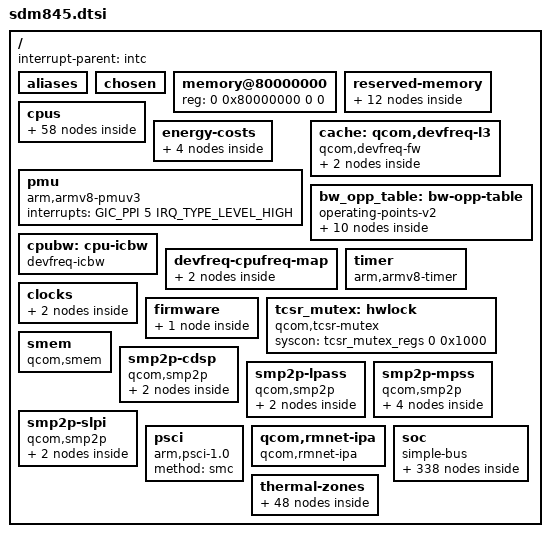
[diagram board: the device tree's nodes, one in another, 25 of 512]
// SPDX-License-Identifier: GPL-2.0
/*
 * SDM845 SoC device tree source
 *
 * Copyright (c) 2018, The Linux Foundation. All rights reserved.
 */

#include <dt-bindings/clock/qcom,aop-qmp.h>
#include <dt-bindings/clock/qcom,dispcc-sdm845.h>
#include <dt-bindings/clock/qcom,gcc-sdm845.h>
#include <dt-bindings/clock/qcom,gpucc-sdm845.h>
#include <dt-bindings/clock/qcom,rpmh.h>
#include <dt-bindings/clock/qcom,videocc-sdm845.h>
#include <dt-bindings/interrupt-controller/arm-gic.h>
#include <dt-bindings/phy/phy-qcom-qusb2.h>
#include <dt-bindings/power/qcom-rpmpd.h>
#include <dt-bindings/reset/qcom,sdm845-aoss.h>
#include <dt-bindings/reset/qcom,sdm845-pdc.h>
#include <dt-bindings/soc/qcom,dcc_v2.h>
#include <dt-bindings/soc/qcom,rpmh-rsc.h>
#include <dt-bindings/soc/qcom,ipa.h>
#include <dt-bindings/thermal/thermal.h>

/ {
	interrupt-parent = <&intc>;

	#address-cells = <2>;
	#size-cells = <2>;

	aliases {
		i2c0 = &i2c0;
		i2c1 = &i2c1;
		i2c2 = &i2c2;
		i2c3 = &i2c3;
		i2c4 = &i2c4;
		i2c5 = &i2c5;
		i2c6 = &i2c6;
		i2c7 = &i2c7;
		i2c8 = &i2c8;
		i2c9 = &i2c9;
		i2c10 = &i2c10;
		i2c11 = &i2c11;
		i2c12 = &i2c12;
		i2c13 = &i2c13;
		i2c14 = &i2c14;
		i2c15 = &i2c15;
		spi0 = &spi0;
		spi1 = &spi1;
		spi2 = &spi2;
		spi3 = &spi3;
		spi4 = &spi4;
		spi5 = &spi5;
		spi6 = &spi6;
		spi7 = &spi7;
		spi8 = &spi8;
		spi9 = &spi9;
		spi10 = &spi10;
		spi11 = &spi11;
		spi12 = &spi12;
		spi13 = &spi13;
		spi14 = &spi14;
		spi15 = &spi15;
	};

	chosen { };

	memory@80000000 {
		device_type = "memory";
		/* We expect the bootloader to fill in the size */
		reg = <0 0x80000000 0 0>;
	};

	reserved-memory {
		#address-cells = <2>;
		#size-cells = <2>;
		ranges;

		memory@85fc0000 {
			reg = <0 0x85fc0000 0 0x20000>;
			no-map;
		};

		memory@85fe0000 {
			compatible = "qcom,cmd-db";
			reg = <0x0 0x85fe0000 0x0 0x20000>;
			no-map;
		};

		smem_mem: memory@86000000 {
			reg = <0x0 0x86000000 0x0 0x200000>;
			no-map;
		};

		memory@86200000 {
			reg = <0 0x86200000 0 0x2d00000>;
			no-map;
		};

		rmtfs_mem: rmtfs@88f00000 {
			compatible = "qcom,rmtfs-mem";
			reg = <0x0 0x88f00000 0x0 0x200000>;
			no-map;

			qcom,client-id = <1>;
		};

		pil_adsp_mem: reserved-memory@8b100000 {
			no-map;
			reg = <0 0x8b100000 0 0x1a00000>;
		};

		mpss_mem: reserved-memory@8e000000 {
			no-map;
			reg = <0 0x8e000000 0 0x7800000>;
		};

		venus_region: venus@95800000 {
			reg = <0x0 0x95800000 0x0 0x500000>;
			no-map;
		};

		mba_mem: reserved-memory@96500000 {
			no-map;
			reg = <0 0x96500000 0 0x200000>;
		};

		wlan_msa_mem: wlan_msa_region@96700000 {
			no-map;
			reg = <0 0x96700000 0 0x100000>;
		};

		dump_mem: mem_dump_region {
			compatible = "shared-dma-pool";
			reusable;
			size = <0 0x2400000>;
		};

		/* global autoconfigured region for contiguous allocations */
		linux,cma {
			compatible = "shared-dma-pool";
			alloc-ranges = <0 0x00000000 0 0xffffffff>;
			reusable;
			alignment = <0 0x400000>;
			size = <0 0x2800000>;
			linux,cma-default;
		};
	};

	cpus {
		#address-cells = <2>;
		#size-cells = <0>;

		CPU0: cpu@0 {
			device_type = "cpu";
			compatible = "qcom,kryo385";
			reg = <0x0 0x0>;
			enable-method = "psci";
			next-level-cache = <&L2_0>;
			cpu-idle-states = <&C0_CPU_PD &C0_CPU_RPD &CLUSTER_PD>;
			qcom,freq-domain = <&cpufreq_hw 0>;
			capacity-dmips-mhz = <607>;
			sched-energy-costs = <&SDM845_CPU_COST_0 &SDM845_CLUSTER_COST_0>;
			freq-energy-model;
			#cooling-cells = <2>; /* min followed by max */
			power-domains = <&cpu_pd>;

			L2_0: l2-cache {
				compatible = "cache";
				next-level-cache = <&L3_0>;
				L3_0: l3-cache {
				      compatible = "cache";
				};
			};

			L1_I_0: l1-icache {
				compatible = "cache";
				qcom,dump-size = <0x9000>;
			};

			L1_D_0: l1-dcache {
				compatible = "cache";
				qcom,dump-size = <0x9000>;
			};

			L1_TLB_0: l1-tlb {
				qcom,dump-size = <0x6000>;
			};
		};

		CPU1: cpu@100 {
			device_type = "cpu";
			compatible = "qcom,kryo385";
			reg = <0x0 0x100>;
			enable-method = "psci";
			next-level-cache = <&L2_100>;
			cpu-idle-states = <&C0_CPU_PD &C0_CPU_RPD &CLUSTER_PD>;
			qcom,freq-domain = <&cpufreq_hw 0>;
			capacity-dmips-mhz = <607>;
			sched-energy-costs = <&SDM845_CPU_COST_0 &SDM845_CLUSTER_COST_0>;
			freq-energy-model;
			power-domains = <&cpu_pd>;

			L2_100: l2-cache {
				compatible = "cache";
				next-level-cache = <&L3_0>;
			};

			L1_I_100: l1-icache {
				compatible = "cache";
				qcom,dump-size = <0x9000>;
			};

			L1_D_100: l1-dcache {
				compatible = "cache";
				qcom,dump-size = <0x9000>;
			};

			L1_TLB_100: l1-tlb {
				qcom,dump-size = <0x6000>;
			};
		};

		CPU2: cpu@200 {
			device_type = "cpu";
			compatible = "qcom,kryo385";
			reg = <0x0 0x200>;
			enable-method = "psci";
			next-level-cache = <&L2_200>;
			cpu-idle-states = <&C0_CPU_PD &C0_CPU_RPD &CLUSTER_PD>;
			qcom,freq-domain = <&cpufreq_hw 0>;
			capacity-dmips-mhz = <607>;
			sched-energy-costs = <&SDM845_CPU_COST_0 &SDM845_CLUSTER_COST_0>;
			freq-energy-model;
			power-domains = <&cpu_pd>;

			L2_200: l2-cache {
				compatible = "cache";
				next-level-cache = <&L3_0>;
			};

			L1_I_200: l1-icache {
				compatible = "cache";
				qcom,dump-size = <0x9000>;
			};

			L1_D_200: l1-dcache {
				compatible = "cache";
				qcom,dump-size = <0x9000>;
			};

			L1_TLB_200: l1-tlb {
				qcom,dump-size = <0x6000>;
			};
		};

		CPU3: cpu@300 {
			device_type = "cpu";
			compatible = "qcom,kryo385";
			reg = <0x0 0x300>;
			enable-method = "psci";
			next-level-cache = <&L2_300>;
			cpu-idle-states = <&C0_CPU_PD &C0_CPU_RPD &CLUSTER_PD>;
			qcom,freq-domain = <&cpufreq_hw 0>;
			capacity-dmips-mhz = <607>;
			sched-energy-costs = <&SDM845_CPU_COST_0 &SDM845_CLUSTER_COST_0>;
			freq-energy-model;
			power-domains = <&cpu_pd>;

			L2_300: l2-cache {
				compatible = "cache";
				next-level-cache = <&L3_0>;
			};

			L1_I_300: l1-icache {
				compatible = "cache";
				qcom,dump-size = <0x9000>;
			};

			L1_D_300: l1-dcache {
				compatible = "cache";
				qcom,dump-size = <0x9000>;
			};

			L1_TLB_300: l1-tlb {
				qcom,dump-size = <0x6000>;
			};
		};

		CPU4: cpu@400 {
			device_type = "cpu";
			compatible = "qcom,kryo385";
			reg = <0x0 0x400>;
			enable-method = "psci";
			next-level-cache = <&L2_400>;
			cpu-idle-states = <&C4_CPU_PD &C4_CPU_RPD &CLUSTER_PD>;
			capacity-dmips-mhz = <1024>;
			qcom,freq-domain = <&cpufreq_hw 1>;
			sched-energy-costs = <&SDM845_CPU_COST_1 &SDM845_CLUSTER_COST_1>;
			freq-energy-model;
			#cooling-cells = <2>; /* min followed by max */
			power-domains = <&cpu_pd>;

			L2_400: l2-cache {
				compatible = "cache";
				next-level-cache = <&L3_0>;
			};

			L1_I_400: l1-icache {
				compatible = "cache";
				qcom,dump-size = <0x12000>;
			};

			L1_D_400: l1-dcache {
				compatible = "cache";
				qcom,dump-size = <0x12000>;
			};

			L1_TLB_400: l1-tlb {
				qcom,dump-size = <0x6800>;
			};
		};

		CPU5: cpu@500 {
			device_type = "cpu";
			compatible = "qcom,kryo385";
			reg = <0x0 0x500>;
			enable-method = "psci";
			next-level-cache = <&L2_500>;
			cpu-idle-states = <&C4_CPU_PD &C4_CPU_RPD &CLUSTER_PD>;
			qcom,freq-domain = <&cpufreq_hw 1>;
			capacity-dmips-mhz = <1024>;
			sched-energy-costs = <&SDM845_CPU_COST_1 &SDM845_CLUSTER_COST_1>;
			freq-energy-model;
			power-domains = <&cpu_pd>;

			L2_500: l2-cache {
				compatible = "cache";
				next-level-cache = <&L3_0>;
			};

			L1_I_500: l1-icache {
				compatible = "cache";
				qcom,dump-size = <0x12000>;
			};

			L1_D_500: l1-dcache {
				compatible = "cache";
				qcom,dump-size = <0x12000>;
			};

			L1_TLB_500: l1-tlb {
				qcom,dump-size = <0x6800>;
			};
		};

		CPU6: cpu@600 {
			device_type = "cpu";
			compatible = "qcom,kryo385";
			reg = <0x0 0x600>;
			enable-method = "psci";
			next-level-cache = <&L2_600>;
			cpu-idle-states = <&C4_CPU_PD &C4_CPU_RPD &CLUSTER_PD>;
			qcom,freq-domain = <&cpufreq_hw 1>;
			capacity-dmips-mhz = <1024>;
			sched-energy-costs = <&SDM845_CPU_COST_1 &SDM845_CLUSTER_COST_1>;
			freq-energy-model;
			power-domains = <&cpu_pd>;

			L2_600: l2-cache {
				compatible = "cache";
				next-level-cache = <&L3_0>;
			};

			L1_I_600: l1-icache {
				compatible = "cache";
				qcom,dump-size = <0x12000>;
			};

			L1_D_600: l1-dcache {
				compatible = "cache";
				qcom,dump-size = <0x12000>;
			};

			L1_TLB_600: l1-tlb {
				qcom,dump-size = <0x6800>;
			};
		};

		CPU7: cpu@700 {
			device_type = "cpu";
			compatible = "qcom,kryo385";
			reg = <0x0 0x700>;
			enable-method = "psci";
			next-level-cache = <&L2_700>;
			cpu-idle-states = <&C4_CPU_PD &C4_CPU_RPD &CLUSTER_PD>;
			qcom,freq-domain = <&cpufreq_hw 1>;
			capacity-dmips-mhz = <1024>;
			sched-energy-costs = <&SDM845_CPU_COST_1 &SDM845_CLUSTER_COST_1>;
			freq-energy-model;
			power-domains = <&cpu_pd>;

			L2_700: l2-cache {
				compatible = "cache";
				next-level-cache = <&L3_0>;
			};

			L1_I_700: l1-icache {
				compatible = "cache";
				qcom,dump-size = <0x12000>;
			};

			L1_D_700: l1-dcache {
				compatible = "cache";
				qcom,dump-size = <0x12000>;
			};

			L1_TLB_700: l1-tlb {
				qcom,dump-size = <0x6800>;
			};
		};

		cpu-map {
			cluster0 {
				core0 {
					cpu = <&CPU0>;
				};

				core1 {
					cpu = <&CPU1>;
				};

				core2 {
					cpu = <&CPU2>;
				};

				core3 {
					cpu = <&CPU3>;
				};
			};

			cluster1 {
				core0 {
					cpu = <&CPU4>;
				};

				core1 {
					cpu = <&CPU5>;
				};

				core2 {
					cpu = <&CPU6>;
				};

				core3 {
					cpu = <&CPU7>;
				};
			};
		};

		idle-states {
			entry-method = "psci";

			C0_CPU_PD: c0-power-down {
				compatible = "arm,idle-state";
				arm,psci-suspend-param = <0x40000003>;
				entry-latency-us = <350>;
				exit-latency-us = <461>;
				min-residency-us = <1890>;
				local-timer-stop;
				idle-state-name = "power-down";
			};

			C0_CPU_RPD: c0-rail-power-down {
				compatible = "arm,idle-state";
				arm,psci-suspend-param = <0x40000004>;
				entry-latency-us = <360>;
				exit-latency-us = <531>;
				min-residency-us = <3934>;
				local-timer-stop;
				idle-state-name = "rail-power-down";
			};

			C4_CPU_PD: c4-power-down {
				compatible = "arm,idle-state";
				arm,psci-suspend-param = <0x40000003>;
				entry-latency-us = <264>;
				exit-latency-us = <621>;
				min-residency-us = <952>;
				local-timer-stop;
				idle-state-name = "power-down";
			};

			C4_CPU_RPD: c4-rail-power-down {
				compatible = "arm,idle-state";
				arm,psci-suspend-param = <0x40000004>;
				entry-latency-us = <702>;
				exit-latency-us = <1061>;
				min-residency-us = <4488>;
				local-timer-stop;
				idle-state-name = "rail-power-down";
			};

			CLUSTER_PD: cluster-power-down {
				compatible = "arm,idle-state";
				arm,psci-suspend-param = <0x400000F4>;
				entry-latency-us = <3263>;
				exit-latency-us = <6562>;
				min-residency-us = <9987>;
				local-timer-stop;
				idle-state-name = "cluster-power-down";
			};
		};
	};

	energy-costs {
		SDM845_CPU_COST_0: sdm845-core-cost0 {
			busy-cost-data = <
				 300000 12
				 403200 17
				 480000 21
				 576000 27
				 652800 31
				 748800 37
				 825600 42
				 902400 47
				 979200 52
				1056000 57
				1132800 62
				1228800 70
				1324800 78
				1420800 89
				1516800 103
				1612800 122
				1689600 141
				1766400 160
			>;
			idle-cost-data = <
				10 8 6 4
			>;
		};

		SDM845_CPU_COST_1: sdm845-core-cost1 {
			busy-cost-data = <
				 300000 189
				 403200 523
				 480000 763
				 576000 1052
				 652800 1273
				 748800 1536
				 825600 1736
				 902400 1926
				 979200 2108
				1056000 2284
				1132800 2456
				1209600 2628
				1286400 2804
				1363200 2992
				1459200 3255
				1536000 3499
				1612800 3786
				1689600 4128
				1766400 4535
				1843200 5019
				1920000 5583
				1996800 6226
				2092800 7120
				2169600 7876
				2246400 8628
				2323200 9344
				2400000 10030
				2476800 10806
				2553600 12045
				2649600 15686
				2707200 19978
				2745600 25586
				2764800 30000
				2784000 35000
				2803200 40000
				2841600 50000
				2956800 60000
			>;
			idle-cost-data = <
				100 80 60 40
			>;
		};

		SDM845_CLUSTER_COST_0: sdm845-cluster-cost0 {
			busy-cost-data = <
				 300000 3
				 403200 4
				 480000 4
				 576000 4
				 652800 5
				 748800 5
				 825600 6
				 902400 7
				 979200 7
				1056000 8
				1132800 9
				1228800 9
				1324800 10
				1420800 11
				1516800 12
				1612800 13
				1689600 15
				1766400 17
			>;
			idle-cost-data = <
				4 3 2 1
			>;
		};

		SDM845_CLUSTER_COST_1: sdm845-cluster-cost1 {
			busy-cost-data = <
				 300000  24
				 403200  24
				 480000  25
				 576000  25
				 652800  26
				 748800  27
				 825600  28
				 902400  29
				 979200  30
				1056000  32
				1132800  34
				1209600  37
				1286400  40
				1363200  45
				1459200  50
				1536000  57
				1612800  64
				1689600  74
				1766400  84
				1843200  96
				1920000 106
				1996800 113
				2092800 120
				2169600 125
				2246400 127
				2323200 130
				2400000 135
				2476800 140
				2553600 145
				2649600 150
				2707200 153
				2745600 155
				2764800 160
				2784000 165
				2803200 170
				2841600 180
				2956800 190
			>;
			idle-cost-data = <
				4 3 2 1
			>;
		};
	};

	pmu {
		compatible = "arm,armv8-pmuv3";
		interrupts = <GIC_PPI 5 IRQ_TYPE_LEVEL_HIGH>;
	};

	cache: qcom,devfreq-l3 {
	       compatible = "qcom,devfreq-fw";
	       reg-names = "en-base", "ftbl-base", "perf-base";
	       reg = <0x0 0x17d41000 0x0 0x4>,
		     <0x0 0x17d41110 0x0 0x600>,
		     <0x0 0x17d41920 0x0 0x4>;

	       qcom,cpu0-l3 {
		       compatible = "qcom,devfreq-fw-voter";
	       };

	       qcom,cpu4-l3 {
		       compatible = "qcom,devfreq-fw-voter";
	       };
	};

	bw_opp_table: bw-opp-table {
		compatible = "operating-points-v2";
		opp-200  {
			opp-hz = /bits/ 64 < 781250 >; /* 200 MHz */
		};
		opp-300 {
			opp-hz = /bits/ 64 < 1171875 >; /* 300 MHz */
		};
		opp-451 {
			opp-hz = /bits/ 64 < 1761718 >; /* 451 MHz */
		};
		opp-547 {
			opp-hz = /bits/ 64 < 2136718 >; /* 547 MHz */
		};
		opp-681 {
			opp-hz = /bits/ 64 < 2660156 >; /* 681 MHz */
		};
		opp-768 {
			opp-hz = /bits/ 64 < 3000000 >; /* 768 MHz */
		};
		opp-1017 {
			opp-hz = /bits/ 64 < 3972656 >; /* 1017 MHz */
		};
		opp-1296 {
			opp-hz = /bits/ 64 < 5062500 >; /* 1296 MHz */
		};
		opp-1555 {
			opp-hz = /bits/ 64 < 6074218 >; /* 1555 MHz */
		};
		opp-1804 {
			opp-hz = /bits/ 64 < 7046875 >; /* 1804 MHz */
		};
	};

	cpubw: cpu-icbw {
		compatible = "devfreq-icbw";
		interconnects = <&qnoc 0 &qnoc 512>;
		operating-points-v2 = <&bw_opp_table>;
	};

	devfreq-cpufreq-map {
		cache-cpufreq {
		       target-dev = <&cache>;
		       cpu-to-dev-map =
				<  300000  300000 >,
				<  480000  403200 >,
				<  652800  480000 >,
				<  748800  576000 >,
				<  902400  652800 >,
				<  979200  748800 >,
				< 1132800  844800 >,
				< 1228800  940800 >,
				< 1324800 1036800 >,
				< 1420800 1132800 >,
				< 1516800 1209600 >,
				< 1689600 1305600 >,
				< 1766400 1401600 >,
				< 2745600 1593600 >;
		};

		cpubw-cpufreq {
		       target-dev = <&cpubw>;
		       cpu-to-dev-map =
				<  300000 1171875 >,
				<  422400 2660156 >,
				<  652800 3000000 >,
				<  883200 6074218 >,
				< 1190400 7046875 >;
		};
	};

	timer {
		compatible = "arm,armv8-timer";
		interrupts = <GIC_PPI 1 IRQ_TYPE_LEVEL_LOW>,
			     <GIC_PPI 2 IRQ_TYPE_LEVEL_LOW>,
			     <GIC_PPI 3 IRQ_TYPE_LEVEL_LOW>,
			     <GIC_PPI 0 IRQ_TYPE_LEVEL_LOW>;
	};

	clocks {
		xo_board: xo-board {
			compatible = "fixed-clock";
			#clock-cells = <0>;
			clock-frequency = <38400000>;
			clock-output-names = "xo_board";
		};

		sleep_clk: sleep-clk {
			compatible = "fixed-clock";
			#clock-cells = <0>;
			clock-frequency = <32764>;
		};
	};

	firmware {
		/* TODO: does this really belong in SoC dtsi file? */
		scm {
			compatible = "qcom,scm-msm8996";
		};
	};

	tcsr_mutex: hwlock {
		compatible = "qcom,tcsr-mutex";
		syscon = <&tcsr_mutex_regs 0 0x1000>;
		#hwlock-cells = <1>;
	};

	smem {
		compatible = "qcom,smem";
		memory-region = <&smem_mem>;
		hwlocks = <&tcsr_mutex 3>;
	};

	smp2p-cdsp {
		compatible = "qcom,smp2p";
		qcom,smem = <94>, <432>;

		interrupts = <GIC_SPI 576 IRQ_TYPE_EDGE_RISING>;

		mboxes = <&apss_shared 6>;

		qcom,local-pid = <0>;
		qcom,remote-pid = <5>;

		cdsp_smp2p_out: master-kernel {
			qcom,entry-name = "master-kernel";
			#qcom,smem-state-cells = <1>;
		};

		cdsp_smp2p_in: slave-kernel {
			qcom,entry-name = "slave-kernel";

			interrupt-controller;
			#interrupt-cells = <2>;
		};
	};

	smp2p-lpass {
		compatible = "qcom,smp2p";
		qcom,smem = <443>, <429>;

		interrupts = <GIC_SPI 158 IRQ_TYPE_EDGE_RISING>;

		mboxes = <&apss_shared 10>;

		qcom,local-pid = <0>;
		qcom,remote-pid = <2>;

		adsp_smp2p_out: master-kernel {
			qcom,entry-name = "master-kernel";
			#qcom,smem-state-cells = <1>;
		};

		adsp_smp2p_in: slave-kernel {
			qcom,entry-name = "slave-kernel";

			interrupt-controller;
			#interrupt-cells = <2>;
		};
	};

	smp2p-mpss {
		compatible = "qcom,smp2p";
		qcom,smem = <435>, <428>;
		interrupts = <GIC_SPI 451 IRQ_TYPE_EDGE_RISING>;
		mboxes = <&apss_shared 14>;
		qcom,local-pid = <0>;
		qcom,remote-pid = <1>;

		modem_smp2p_out: master-kernel {
			qcom,entry-name = "master-kernel";
			#qcom,smem-state-cells = <1>;
		};

		modem_smp2p_in: slave-kernel {
			qcom,entry-name = "slave-kernel";
			interrupt-controller;
			#interrupt-cells = <2>;
		};

		ipa_smp2p_out: ipa-ap-to-modem {
			qcom,entry-name = "ipa";
			#qcom,smem-state-cells = <1>;
		};

		ipa_smp2p_in: ipa-modem-to-ap {
			qcom,entry-name = "ipa";
			interrupt-controller;
			#interrupt-cells = <2>;
		};
	};

	smp2p-slpi {
		compatible = "qcom,smp2p";
		qcom,smem = <481>, <430>;
		interrupts = <GIC_SPI 172 IRQ_TYPE_EDGE_RISING>;
		mboxes = <&apss_shared 26>;
		qcom,local-pid = <0>;
		qcom,remote-pid = <3>;

		slpi_smp2p_out: master-kernel {
			qcom,entry-name = "master-kernel";
			#qcom,smem-state-cells = <1>;
		};

		slpi_smp2p_in: slave-kernel {
			qcom,entry-name = "slave-kernel";
			interrupt-controller;
			#interrupt-cells = <2>;
		};
	};

	psci {
		compatible = "arm,psci-1.0";
		method = "smc";
	};

	qcom,rmnet-ipa {
		compatible = "qcom,rmnet-ipa";
	};

	soc: soc {
		#address-cells = <1>;
		#size-cells = <1>;
		ranges = <0 0 0 0xffffffff>;
		compatible = "simple-bus";

		maxvoter {
			compatible = "qcom,maxvoter";
			power-domains = <&rpmhpd SDM845_MX>,
					<&rpmhpd SDM845_CX>;
			power-domain-names = "mx", "cx";
		};

		cpuss_dump {
			compatible = "qcom,cpuss-dump";
			qcom,l1_i_cache0 {
				qcom,dump-node = <&L1_I_0>;
				qcom,dump-id = <0x60>;
			};
			qcom,l1_i_cache1 {
				qcom,dump-node = <&L1_I_100>;
				qcom,dump-id = <0x61>;
			};
			qcom,l1_i_cache2 {
				qcom,dump-node = <&L1_I_200>;
				qcom,dump-id = <0x62>;
			};
			qcom,l1_i_cache3 {
				qcom,dump-node = <&L1_I_300>;
				qcom,dump-id = <0x63>;
			};
			qcom,l1_i_cache100 {
				qcom,dump-node = <&L1_I_400>;
				qcom,dump-id = <0x64>;
			};
			qcom,l1_i_cache101 {
				qcom,dump-node = <&L1_I_500>;
				qcom,dump-id = <0x65>;
			};
			qcom,l1_i_cache102 {
				qcom,dump-node = <&L1_I_600>;
				qcom,dump-id = <0x66>;
			};
			qcom,l1_i_cache103 {
				qcom,dump-node = <&L1_I_700>;
				qcom,dump-id = <0x67>;
			};
			qcom,l1_d_cache0 {
				qcom,dump-node = <&L1_D_0>;
				qcom,dump-id = <0x80>;
			};
			qcom,l1_d_cache1 {
				qcom,dump-node = <&L1_D_100>;
				qcom,dump-id = <0x81>;
			};
			qcom,l1_d_cache2 {
				qcom,dump-node = <&L1_D_200>;
				qcom,dump-id = <0x82>;
			};
			qcom,l1_d_cache3 {
				qcom,dump-node = <&L1_D_300>;
				qcom,dump-id = <0x83>;
			};
			qcom,l1_d_cache100 {
				qcom,dump-node = <&L1_D_400>;
				qcom,dump-id = <0x84>;
			};
			qcom,l1_d_cache101 {
				qcom,dump-node = <&L1_D_500>;
				qcom,dump-id = <0x85>;
			};
			qcom,l1_d_cache102 {
				qcom,dump-node = <&L1_D_600>;
				qcom,dump-id = <0x86>;
			};
			qcom,l1_d_cache103 {
				qcom,dump-node = <&L1_D_700>;
				qcom,dump-id = <0x87>;
			};
			qcom,l1_tlb_dump0 {
				qcom,dump-node = <&L1_TLB_0>;
				qcom,dump-id = <0x120>;
			};
			qcom,l1_tlb_dump100 {
				qcom,dump-node = <&L1_TLB_100>;
				qcom,dump-id = <0x121>;
			};
			qcom,l1_tlb_dump200 {
				qcom,dump-node = <&L1_TLB_200>;
				qcom,dump-id = <0x122>;
			};
			qcom,l1_tlb_dump300 {
				qcom,dump-node = <&L1_TLB_300>;
				qcom,dump-id = <0x123>;
			};
			qcom,l1_tlb_dump400 {
				qcom,dump-node = <&L1_TLB_400>;
				qcom,dump-id = <0x124>;
			};
			qcom,l1_tlb_dump500 {
				qcom,dump-node = <&L1_TLB_500>;
				qcom,dump-id = <0x125>;
			};
			qcom,l1_tlb_dump600 {
				qcom,dump-node = <&L1_TLB_600>;
				qcom,dump-id = <0x126>;
			};
			qcom,l1_tlb_dump700 {
				qcom,dump-node = <&L1_TLB_700>;
				qcom,dump-id = <0x127>;
			};
		};

		gcc: clock-controller@100000 {
			compatible = "qcom,gcc-sdm845";
			reg = <0x100000 0x1f0000>;
			#clock-cells = <1>;
			#reset-cells = <1>;
			#power-domain-cells = <1>;
		};

		lpasscc: clock-controller {
			compatible = "qcom,sdm845-lpasscc";
			reg = <0x17014000 0x1f004>, <0x17300000 0x200>;
			reg-names = "lpass_cc", "lpass_qdsp6ss";
			#clock-cells = <1>;
		};

		clock_aop: qcom,aopclk {
			compatible = "qcom,aop-qmp-clk";
			#clock-cells = <1>;
			mboxes = <&qmp_aop 0>;
			mbox-names = "qdss_clk";
		};

		qfprom@784000 {
			compatible = "qcom,qfprom";
			reg = <0x784000 0x8ff>;
			#address-cells = <1>;
			#size-cells = <1>;

			qusb2p_hstx_trim: hstx-trim-primary@1eb {
				reg = <0x1eb 0x1>;
				bits = <1 4>;
			};

			qusb2s_hstx_trim: hstx-trim-secondary@1eb {
				reg = <0x1eb 0x2>;
				bits = <6 4>;
			};
		};

		qupv3_id_0: geniqup@8c0000 {
			compatible = "qcom,geni-se-qup";
			reg = <0x8c0000 0x6000>;
			clock-names = "m-ahb", "s-ahb";
			clocks = <&gcc GCC_QUPV3_WRAP_0_M_AHB_CLK>,
				 <&gcc GCC_QUPV3_WRAP_0_S_AHB_CLK>;
			#address-cells = <1>;
			#size-cells = <1>;
			ranges;
			status = "disabled";

			i2c0: i2c@880000 {
				compatible = "qcom,geni-i2c";
				reg = <0x880000 0x4000>;
				clock-names = "se";
				clocks = <&gcc GCC_QUPV3_WRAP0_S0_CLK>;
				pinctrl-names = "default";
				pinctrl-0 = <&qup_i2c0_default>;
				interrupts = <GIC_SPI 601 IRQ_TYPE_LEVEL_HIGH>;
				#address-cells = <1>;
				#size-cells = <0>;

				interconnects = <&qnoc 11 &qnoc 512>,
						<&qnoc 0 &qnoc 543>;
				interconnect-names = "memory", "config";

				status = "disabled";
			};

			spi0: spi@880000 {
				compatible = "qcom,geni-spi";
				reg = <0x880000 0x4000>;
				clock-names = "se";
				clocks = <&gcc GCC_QUPV3_WRAP0_S0_CLK>;
				pinctrl-names = "default";
				pinctrl-0 = <&qup_spi0_default>;
				interrupts = <GIC_SPI 601 IRQ_TYPE_LEVEL_HIGH>;
				#address-cells = <1>;
				#size-cells = <0>;

				interconnects = <&qnoc 11 &qnoc 512>,
						<&qnoc 0 &qnoc 543>;
				interconnect-names = "memory", "config";

				status = "disabled";
			};

			uart0: serial@880000 {
				compatible = "qcom,geni-uart";
				reg = <0x880000 0x4000>;
				clock-names = "se";
				clocks = <&gcc GCC_QUPV3_WRAP0_S0_CLK>;
				pinctrl-names = "default";
				pinctrl-0 = <&qup_uart0_default>;
				interrupts = <GIC_SPI 601 IRQ_TYPE_LEVEL_HIGH>;
				status = "disabled";
			};

			i2c1: i2c@884000 {
				compatible = "qcom,geni-i2c";
				reg = <0x884000 0x4000>;
				clock-names = "se";
				clocks = <&gcc GCC_QUPV3_WRAP0_S1_CLK>;
				pinctrl-names = "default";
				pinctrl-0 = <&qup_i2c1_default>;
				interrupts = <GIC_SPI 602 IRQ_TYPE_LEVEL_HIGH>;
				#address-cells = <1>;
				#size-cells = <0>;

				interconnects = <&qnoc 11 &qnoc 512>,
						<&qnoc 0 &qnoc 543>;
				interconnect-names = "memory", "config";

				status = "disabled";
			};

			spi1: spi@884000 {
				compatible = "qcom,geni-spi";
				reg = <0x884000 0x4000>;
				clock-names = "se";
				clocks = <&gcc GCC_QUPV3_WRAP0_S1_CLK>;
				pinctrl-names = "default";
				pinctrl-0 = <&qup_spi1_default>;
				interrupts = <GIC_SPI 602 IRQ_TYPE_LEVEL_HIGH>;
				#address-cells = <1>;
				#size-cells = <0>;

				interconnects = <&qnoc 11 &qnoc 512>,
						<&qnoc 0 &qnoc 543>;
				interconnect-names = "memory", "config";

				status = "disabled";
			};

			uart1: serial@884000 {
				compatible = "qcom,geni-uart";
				reg = <0x884000 0x4000>;
				clock-names = "se";
				clocks = <&gcc GCC_QUPV3_WRAP0_S1_CLK>;
				pinctrl-names = "default";
				pinctrl-0 = <&qup_uart1_default>;
				interrupts = <GIC_SPI 602 IRQ_TYPE_LEVEL_HIGH>;
				status = "disabled";
			};

			i2c2: i2c@888000 {
				compatible = "qcom,geni-i2c";
				reg = <0x888000 0x4000>;
				clock-names = "se";
				clocks = <&gcc GCC_QUPV3_WRAP0_S2_CLK>;
				pinctrl-names = "default";
				pinctrl-0 = <&qup_i2c2_default>;
				interrupts = <GIC_SPI 603 IRQ_TYPE_LEVEL_HIGH>;
				#address-cells = <1>;
				#size-cells = <0>;

				interconnects = <&qnoc 11 &qnoc 512>,
						<&qnoc 0 &qnoc 543>;
				interconnect-names = "memory", "config";

				status = "disabled";
			};

			spi2: spi@888000 {
				compatible = "qcom,geni-spi";
				reg = <0x888000 0x4000>;
				clock-names = "se";
				clocks = <&gcc GCC_QUPV3_WRAP0_S2_CLK>;
				pinctrl-names = "default";
				pinctrl-0 = <&qup_spi2_default>;
				interrupts = <GIC_SPI 603 IRQ_TYPE_LEVEL_HIGH>;
				#address-cells = <1>;
				#size-cells = <0>;

				interconnects = <&qnoc 11 &qnoc 512>,
						<&qnoc 0 &qnoc 543>;
				interconnect-names = "memory", "config";

				status = "disabled";
			};

			uart2: serial@888000 {
				compatible = "qcom,geni-uart";
				reg = <0x888000 0x4000>;
				clock-names = "se";
				clocks = <&gcc GCC_QUPV3_WRAP0_S2_CLK>;
				pinctrl-names = "default";
				pinctrl-0 = <&qup_uart2_default>;
				interrupts = <GIC_SPI 603 IRQ_TYPE_LEVEL_HIGH>;
				status = "disabled";
			};

			i2c3: i2c@88c000 {
				compatible = "qcom,geni-i2c";
				reg = <0x88c000 0x4000>;
				clock-names = "se";
				clocks = <&gcc GCC_QUPV3_WRAP0_S3_CLK>;
				pinctrl-names = "default";
				pinctrl-0 = <&qup_i2c3_default>;
				interrupts = <GIC_SPI 604 IRQ_TYPE_LEVEL_HIGH>;
				#address-cells = <1>;
				#size-cells = <0>;

				interconnects = <&qnoc 11 &qnoc 512>,
						<&qnoc 0 &qnoc 543>;
				interconnect-names = "memory", "config";

				status = "disabled";
			};

			spi3: spi@88c000 {
				compatible = "qcom,geni-spi";
				reg = <0x88c000 0x4000>;
				clock-names = "se";
				clocks = <&gcc GCC_QUPV3_WRAP0_S3_CLK>;
				pinctrl-names = "default";
				pinctrl-0 = <&qup_spi3_default>;
				interrupts = <GIC_SPI 604 IRQ_TYPE_LEVEL_HIGH>;
				#address-cells = <1>;
				#size-cells = <0>;

				interconnects = <&qnoc 11 &qnoc 512>,
						<&qnoc 0 &qnoc 543>;
				interconnect-names = "memory", "config";

				status = "disabled";
			};

			uart3: serial@88c000 {
				compatible = "qcom,geni-uart";
				reg = <0x88c000 0x4000>;
				clock-names = "se";
				clocks = <&gcc GCC_QUPV3_WRAP0_S3_CLK>;
				pinctrl-names = "default";
				pinctrl-0 = <&qup_uart3_default>;
				interrupts = <GIC_SPI 604 IRQ_TYPE_LEVEL_HIGH>;
				status = "disabled";
			};

			i2c4: i2c@890000 {
				compatible = "qcom,geni-i2c";
				reg = <0x890000 0x4000>;
				clock-names = "se";
				clocks = <&gcc GCC_QUPV3_WRAP0_S4_CLK>;
				pinctrl-names = "default";
				pinctrl-0 = <&qup_i2c4_default>;
				interrupts = <GIC_SPI 605 IRQ_TYPE_LEVEL_HIGH>;
				#address-cells = <1>;
				#size-cells = <0>;

				interconnects = <&qnoc 11 &qnoc 512>,
						<&qnoc 0 &qnoc 543>;
				interconnect-names = "memory", "config";

				status = "disabled";
			};

			spi4: spi@890000 {
				compatible = "qcom,geni-spi";
				reg = <0x890000 0x4000>;
				clock-names = "se";
				clocks = <&gcc GCC_QUPV3_WRAP0_S4_CLK>;
				pinctrl-names = "default";
				pinctrl-0 = <&qup_spi4_default>;
				interrupts = <GIC_SPI 605 IRQ_TYPE_LEVEL_HIGH>;
				#address-cells = <1>;
				#size-cells = <0>;

				interconnects = <&qnoc 11 &qnoc 512>,
						<&qnoc 0 &qnoc 543>;
				interconnect-names = "memory", "config";

				status = "disabled";
			};

			uart4: serial@890000 {
				compatible = "qcom,geni-uart";
				reg = <0x890000 0x4000>;
				clock-names = "se";
				clocks = <&gcc GCC_QUPV3_WRAP0_S4_CLK>;
				pinctrl-names = "default";
				pinctrl-0 = <&qup_uart4_default>;
				interrupts = <GIC_SPI 605 IRQ_TYPE_LEVEL_HIGH>;
				status = "disabled";
			};

			i2c5: i2c@894000 {
				compatible = "qcom,geni-i2c";
				reg = <0x894000 0x4000>;
				clock-names = "se";
				clocks = <&gcc GCC_QUPV3_WRAP0_S5_CLK>;
				pinctrl-names = "default";
				pinctrl-0 = <&qup_i2c5_default>;
				interrupts = <GIC_SPI 606 IRQ_TYPE_LEVEL_HIGH>;
				#address-cells = <1>;
				#size-cells = <0>;

				interconnects = <&qnoc 11 &qnoc 512>,
						<&qnoc 0 &qnoc 543>;
				interconnect-names = "memory", "config";

				status = "disabled";
			};

			spi5: spi@894000 {
				compatible = "qcom,geni-spi";
				reg = <0x894000 0x4000>;
				clock-names = "se";
				clocks = <&gcc GCC_QUPV3_WRAP0_S5_CLK>;
				pinctrl-names = "default";
				pinctrl-0 = <&qup_spi5_default>;
				interrupts = <GIC_SPI 606 IRQ_TYPE_LEVEL_HIGH>;
				#address-cells = <1>;
				#size-cells = <0>;

				interconnects = <&qnoc 11 &qnoc 512>,
						<&qnoc 0 &qnoc 543>;
				interconnect-names = "memory", "config";

				status = "disabled";
			};

			uart5: serial@894000 {
				compatible = "qcom,geni-uart";
				reg = <0x894000 0x4000>;
				clock-names = "se";
				clocks = <&gcc GCC_QUPV3_WRAP0_S5_CLK>;
				pinctrl-names = "default";
				pinctrl-0 = <&qup_uart5_default>;
				interrupts = <GIC_SPI 606 IRQ_TYPE_LEVEL_HIGH>;
				status = "disabled";
			};

			i2c6: i2c@898000 {
				compatible = "qcom,geni-i2c";
				reg = <0x898000 0x4000>;
				clock-names = "se";
				clocks = <&gcc GCC_QUPV3_WRAP0_S6_CLK>;
				pinctrl-names = "default";
				pinctrl-0 = <&qup_i2c6_default>;
				interrupts = <GIC_SPI 607 IRQ_TYPE_LEVEL_HIGH>;
				#address-cells = <1>;
				#size-cells = <0>;

				interconnects = <&qnoc 11 &qnoc 512>,
						<&qnoc 0 &qnoc 543>;
				interconnect-names = "memory", "config";

				status = "disabled";
			};

			spi6: spi@898000 {
				compatible = "qcom,geni-spi";
				reg = <0x898000 0x4000>;
				clock-names = "se";
				clocks = <&gcc GCC_QUPV3_WRAP0_S6_CLK>;
				pinctrl-names = "default";
				pinctrl-0 = <&qup_spi6_default>;
				interrupts = <GIC_SPI 607 IRQ_TYPE_LEVEL_HIGH>;
				#address-cells = <1>;
				#size-cells = <0>;

				interconnects = <&qnoc 11 &qnoc 512>,
						<&qnoc 0 &qnoc 543>;
				interconnect-names = "memory", "config";

				status = "disabled";
			};

			uart6: serial@898000 {
				compatible = "qcom,geni-uart";
				reg = <0x898000 0x4000>;
				clock-names = "se";
				clocks = <&gcc GCC_QUPV3_WRAP0_S6_CLK>;
				pinctrl-names = "default";
				pinctrl-0 = <&qup_uart6_default>;
				interrupts = <GIC_SPI 607 IRQ_TYPE_LEVEL_HIGH>;

				interconnects = <&qnoc 11 &qnoc 512>,
						<&qnoc 0 &qnoc 543>;
				interconnect-names = "memory", "config";

				status = "disabled";
			};

			i2c7: i2c@89c000 {
				compatible = "qcom,geni-i2c";
				reg = <0x89c000 0x4000>;
				clock-names = "se";
				clocks = <&gcc GCC_QUPV3_WRAP0_S7_CLK>;
				pinctrl-names = "default";
				pinctrl-0 = <&qup_i2c7_default>;
				interrupts = <GIC_SPI 608 IRQ_TYPE_LEVEL_HIGH>;
				#address-cells = <1>;
				#size-cells = <0>;

				interconnects = <&qnoc 11 &qnoc 512>,
						<&qnoc 0 &qnoc 543>;
				interconnect-names = "memory", "config";

				status = "disabled";
			};

			spi7: spi@89c000 {
				compatible = "qcom,geni-spi";
				reg = <0x89c000 0x4000>;
				clock-names = "se";
				clocks = <&gcc GCC_QUPV3_WRAP0_S7_CLK>;
				pinctrl-names = "default";
				pinctrl-0 = <&qup_spi7_default>;
				interrupts = <GIC_SPI 608 IRQ_TYPE_LEVEL_HIGH>;
				#address-cells = <1>;
				#size-cells = <0>;

				interconnects = <&qnoc 11 &qnoc 512>,
						<&qnoc 0 &qnoc 543>;
				interconnect-names = "memory", "config";

				status = "disabled";
			};

			uart7: serial@89c000 {
				compatible = "qcom,geni-uart";
				reg = <0x89c000 0x4000>;
				clock-names = "se";
				clocks = <&gcc GCC_QUPV3_WRAP0_S7_CLK>;
				pinctrl-names = "default";
				pinctrl-0 = <&qup_uart7_default>;
				interrupts = <GIC_SPI 608 IRQ_TYPE_LEVEL_HIGH>;
				status = "disabled";
			};
		};

		qupv3_id_1: geniqup@ac0000 {
			compatible = "qcom,geni-se-qup";
			reg = <0xac0000 0x6000>;
			clock-names = "m-ahb", "s-ahb";
			clocks = <&gcc GCC_QUPV3_WRAP_1_M_AHB_CLK>,
				 <&gcc GCC_QUPV3_WRAP_1_S_AHB_CLK>;
			#address-cells = <1>;
			#size-cells = <1>;
			ranges;
			status = "disabled";

			i2c8: i2c@a80000 {
				compatible = "qcom,geni-i2c";
				reg = <0xa80000 0x4000>;
				clock-names = "se";
				clocks = <&gcc GCC_QUPV3_WRAP1_S0_CLK>;
				pinctrl-names = "default";
				pinctrl-0 = <&qup_i2c8_default>;
				interrupts = <GIC_SPI 353 IRQ_TYPE_LEVEL_HIGH>;
				#address-cells = <1>;
				#size-cells = <0>;

				interconnects = <&qnoc 12 &qnoc 512>,
						<&qnoc 0 &qnoc 542>;
				interconnect-names = "memory", "config";

				status = "disabled";
			};

			spi8: spi@a80000 {
				compatible = "qcom,geni-spi";
				reg = <0xa80000 0x4000>;
				clock-names = "se";
				clocks = <&gcc GCC_QUPV3_WRAP1_S0_CLK>;
				pinctrl-names = "default";
				pinctrl-0 = <&qup_spi8_default>;
				interrupts = <GIC_SPI 353 IRQ_TYPE_LEVEL_HIGH>;
				#address-cells = <1>;
				#size-cells = <0>;

				interconnects = <&qnoc 12 &qnoc 512>,
						<&qnoc 0 &qnoc 542>;
				interconnect-names = "memory", "config";

				status = "disabled";
			};

			uart8: serial@a80000 {
				compatible = "qcom,geni-uart";
				reg = <0xa80000 0x4000>;
				clock-names = "se";
				clocks = <&gcc GCC_QUPV3_WRAP1_S0_CLK>;
				pinctrl-names = "default";
				pinctrl-0 = <&qup_uart8_default>;
				interrupts = <GIC_SPI 353 IRQ_TYPE_LEVEL_HIGH>;
				status = "disabled";
			};

			i2c9: i2c@a84000 {
				compatible = "qcom,geni-i2c";
				reg = <0xa84000 0x4000>;
				clock-names = "se";
				clocks = <&gcc GCC_QUPV3_WRAP1_S1_CLK>;
				pinctrl-names = "default";
				pinctrl-0 = <&qup_i2c9_default>;
				interrupts = <GIC_SPI 354 IRQ_TYPE_LEVEL_HIGH>;
				#address-cells = <1>;
				#size-cells = <0>;

				interconnects = <&qnoc 12 &qnoc 512>,
						<&qnoc 0 &qnoc 542>;
				interconnect-names = "memory", "config";

				status = "disabled";
			};

			spi9: spi@a84000 {
				compatible = "qcom,geni-spi";
				reg = <0xa84000 0x4000>;
				clock-names = "se";
				clocks = <&gcc GCC_QUPV3_WRAP1_S1_CLK>;
				pinctrl-names = "default";
				pinctrl-0 = <&qup_spi9_default>;
				interrupts = <GIC_SPI 354 IRQ_TYPE_LEVEL_HIGH>;
				#address-cells = <1>;
				#size-cells = <0>;

				interconnects = <&qnoc 12 &qnoc 512>,
						<&qnoc 0 &qnoc 542>;
				interconnect-names = "memory", "config";

				status = "disabled";
			};

			uart9: serial@a84000 {
				compatible = "qcom,geni-debug-uart";
				reg = <0xa84000 0x4000>;
				clock-names = "se";
				clocks = <&gcc GCC_QUPV3_WRAP1_S1_CLK>;
				pinctrl-names = "default";
				pinctrl-0 = <&qup_uart9_default>;
				interrupts = <GIC_SPI 354 IRQ_TYPE_LEVEL_HIGH>;

				interconnects = <&qnoc 12 &qnoc 512>,
						<&qnoc 0 &qnoc 542>;
				interconnect-names = "memory", "config";

				status = "disabled";
			};

			i2c10: i2c@a88000 {
				compatible = "qcom,geni-i2c";
				reg = <0xa88000 0x4000>;
				clock-names = "se";
				clocks = <&gcc GCC_QUPV3_WRAP1_S2_CLK>;
				pinctrl-names = "default";
				pinctrl-0 = <&qup_i2c10_default>;
				interrupts = <GIC_SPI 355 IRQ_TYPE_LEVEL_HIGH>;
				#address-cells = <1>;
				#size-cells = <0>;

				interconnects = <&qnoc 12 &qnoc 512>,
						<&qnoc 0 &qnoc 542>;
				interconnect-names = "memory", "config";

				status = "disabled";
			};

			spi10: spi@a88000 {
				compatible = "qcom,geni-spi";
				reg = <0xa88000 0x4000>;
				clock-names = "se";
				clocks = <&gcc GCC_QUPV3_WRAP1_S2_CLK>;
				pinctrl-names = "default";
				pinctrl-0 = <&qup_spi10_default>;
				interrupts = <GIC_SPI 355 IRQ_TYPE_LEVEL_HIGH>;
				#address-cells = <1>;
				#size-cells = <0>;

				interconnects = <&qnoc 12 &qnoc 512>,
						<&qnoc 0 &qnoc 542>;
				interconnect-names = "memory", "config";

				status = "disabled";
			};

			uart10: serial@a88000 {
				compatible = "qcom,geni-uart";
				reg = <0xa88000 0x4000>;
				clock-names = "se";
				clocks = <&gcc GCC_QUPV3_WRAP1_S2_CLK>;
				pinctrl-names = "default";
				pinctrl-0 = <&qup_uart10_default>;
				interrupts = <GIC_SPI 355 IRQ_TYPE_LEVEL_HIGH>;
				status = "disabled";
			};

			i2c11: i2c@a8c000 {
				compatible = "qcom,geni-i2c";
				reg = <0xa8c000 0x4000>;
				clock-names = "se";
				clocks = <&gcc GCC_QUPV3_WRAP1_S3_CLK>;
				pinctrl-names = "default";
				pinctrl-0 = <&qup_i2c11_default>;
				interrupts = <GIC_SPI 356 IRQ_TYPE_LEVEL_HIGH>;
				#address-cells = <1>;
				#size-cells = <0>;

				interconnects = <&qnoc 12 &qnoc 512>,
						<&qnoc 0 &qnoc 542>;
				interconnect-names = "memory", "config";

				status = "disabled";
			};

			spi11: spi@a8c000 {
				compatible = "qcom,geni-spi";
				reg = <0xa8c000 0x4000>;
				clock-names = "se";
				clocks = <&gcc GCC_QUPV3_WRAP1_S3_CLK>;
				pinctrl-names = "default";
				pinctrl-0 = <&qup_spi11_default>;
				interrupts = <GIC_SPI 356 IRQ_TYPE_LEVEL_HIGH>;
				#address-cells = <1>;
				#size-cells = <0>;

				interconnects = <&qnoc 12 &qnoc 512>,
						<&qnoc 0 &qnoc 542>;
				interconnect-names = "memory", "config";

				status = "disabled";
			};

			uart11: serial@a8c000 {
				compatible = "qcom,geni-uart";
				reg = <0xa8c000 0x4000>;
				clock-names = "se";
				clocks = <&gcc GCC_QUPV3_WRAP1_S3_CLK>;
				pinctrl-names = "default";
				pinctrl-0 = <&qup_uart11_default>;
				interrupts = <GIC_SPI 356 IRQ_TYPE_LEVEL_HIGH>;
				status = "disabled";
			};

			i2c12: i2c@a90000 {
				compatible = "qcom,geni-i2c";
				reg = <0xa90000 0x4000>;
				clock-names = "se";
				clocks = <&gcc GCC_QUPV3_WRAP1_S4_CLK>;
				pinctrl-names = "default";
				pinctrl-0 = <&qup_i2c12_default>;
				interrupts = <GIC_SPI 357 IRQ_TYPE_LEVEL_HIGH>;
				#address-cells = <1>;
				#size-cells = <0>;

				interconnects = <&qnoc 12 &qnoc 512>,
						<&qnoc 0 &qnoc 542>;
				interconnect-names = "memory", "config";

				status = "disabled";
			};

			spi12: spi@a90000 {
				compatible = "qcom,geni-spi";
				reg = <0xa90000 0x4000>;
				clock-names = "se";
				clocks = <&gcc GCC_QUPV3_WRAP1_S4_CLK>;
				pinctrl-names = "default";
				pinctrl-0 = <&qup_spi12_default>;
				interrupts = <GIC_SPI 357 IRQ_TYPE_LEVEL_HIGH>;
				#address-cells = <1>;
				#size-cells = <0>;

				interconnects = <&qnoc 12 &qnoc 512>,
						<&qnoc 0 &qnoc 542>;
				interconnect-names = "memory", "config";

				status = "disabled";
			};

			uart12: serial@a90000 {
				compatible = "qcom,geni-uart";
				reg = <0xa90000 0x4000>;
				clock-names = "se";
				clocks = <&gcc GCC_QUPV3_WRAP1_S4_CLK>;
				pinctrl-names = "default";
				pinctrl-0 = <&qup_uart12_default>;
				interrupts = <GIC_SPI 357 IRQ_TYPE_LEVEL_HIGH>;
				status = "disabled";
			};

			i2c13: i2c@a94000 {
				compatible = "qcom,geni-i2c";
				reg = <0xa94000 0x4000>;
				clock-names = "se";
				clocks = <&gcc GCC_QUPV3_WRAP1_S5_CLK>;
				pinctrl-names = "default";
				pinctrl-0 = <&qup_i2c13_default>;
				interrupts = <GIC_SPI 358 IRQ_TYPE_LEVEL_HIGH>;
				#address-cells = <1>;
				#size-cells = <0>;

				interconnects = <&qnoc 12 &qnoc 512>,
						<&qnoc 0 &qnoc 542>;
				interconnect-names = "memory", "config";

				status = "disabled";
			};

			spi13: spi@a94000 {
				compatible = "qcom,geni-spi";
				reg = <0xa94000 0x4000>;
				clock-names = "se";
				clocks = <&gcc GCC_QUPV3_WRAP1_S5_CLK>;
				pinctrl-names = "default";
				pinctrl-0 = <&qup_spi13_default>;
				interrupts = <GIC_SPI 358 IRQ_TYPE_LEVEL_HIGH>;
				#address-cells = <1>;
				#size-cells = <0>;

				interconnects = <&qnoc 12 &qnoc 512>,
						<&qnoc 0 &qnoc 542>;
				interconnect-names = "memory", "config";

				status = "disabled";
			};

			uart13: serial@a94000 {
				compatible = "qcom,geni-uart";
				reg = <0xa94000 0x4000>;
				clock-names = "se";
				clocks = <&gcc GCC_QUPV3_WRAP1_S5_CLK>;
				pinctrl-names = "default";
				pinctrl-0 = <&qup_uart13_default>;
				interrupts = <GIC_SPI 358 IRQ_TYPE_LEVEL_HIGH>;
				status = "disabled";
			};

			i2c14: i2c@a98000 {
				compatible = "qcom,geni-i2c";
				reg = <0xa98000 0x4000>;
				clock-names = "se";
				clocks = <&gcc GCC_QUPV3_WRAP1_S6_CLK>;
				pinctrl-names = "default";
				pinctrl-0 = <&qup_i2c14_default>;
				interrupts = <GIC_SPI 359 IRQ_TYPE_LEVEL_HIGH>;
				#address-cells = <1>;
				#size-cells = <0>;

				interconnects = <&qnoc 12 &qnoc 512>,
						<&qnoc 0 &qnoc 542>;
				interconnect-names = "memory", "config";

				status = "disabled";
			};

			spi14: spi@a98000 {
				compatible = "qcom,geni-spi";
				reg = <0xa98000 0x4000>;
				clock-names = "se";
				clocks = <&gcc GCC_QUPV3_WRAP1_S6_CLK>;
				pinctrl-names = "default";
				pinctrl-0 = <&qup_spi14_default>;
				interrupts = <GIC_SPI 359 IRQ_TYPE_LEVEL_HIGH>;
				#address-cells = <1>;
				#size-cells = <0>;

				interconnects = <&qnoc 12 &qnoc 512>,
						<&qnoc 0 &qnoc 542>;
				interconnect-names = "memory", "config";

				status = "disabled";
			};

			uart14: serial@a98000 {
				compatible = "qcom,geni-uart";
				reg = <0xa98000 0x4000>;
				clock-names = "se";
				clocks = <&gcc GCC_QUPV3_WRAP1_S6_CLK>;
				pinctrl-names = "default";
				pinctrl-0 = <&qup_uart14_default>;
				interrupts = <GIC_SPI 359 IRQ_TYPE_LEVEL_HIGH>;
				status = "disabled";
			};

			i2c15: i2c@a9c000 {
				compatible = "qcom,geni-i2c";
				reg = <0xa9c000 0x4000>;
				clock-names = "se";
				clocks = <&gcc GCC_QUPV3_WRAP1_S7_CLK>;
				pinctrl-names = "default";
				pinctrl-0 = <&qup_i2c15_default>;
				interrupts = <GIC_SPI 360 IRQ_TYPE_LEVEL_HIGH>;
				#address-cells = <1>;
				#size-cells = <0>;

				interconnects = <&qnoc 12 &qnoc 512>,
						<&qnoc 0 &qnoc 542>;
				interconnect-names = "memory", "config";

				status = "disabled";
			};

			spi15: spi@a9c000 {
				compatible = "qcom,geni-spi";
				reg = <0xa9c000 0x4000>;
				clock-names = "se";
				clocks = <&gcc GCC_QUPV3_WRAP1_S7_CLK>;
				pinctrl-names = "default";
				pinctrl-0 = <&qup_spi15_default>;
				interrupts = <GIC_SPI 360 IRQ_TYPE_LEVEL_HIGH>;
				#address-cells = <1>;
				#size-cells = <0>;

				interconnects = <&qnoc 12 &qnoc 512>,
						<&qnoc 0 &qnoc 542>;
				interconnect-names = "memory", "config";

				status = "disabled";
			};

			uart15: serial@a9c000 {
				compatible = "qcom,geni-uart";
				reg = <0xa9c000 0x4000>;
				clock-names = "se";
				clocks = <&gcc GCC_QUPV3_WRAP1_S7_CLK>;
				pinctrl-names = "default";
				pinctrl-0 = <&qup_uart15_default>;
				interrupts = <GIC_SPI 360 IRQ_TYPE_LEVEL_HIGH>;
				status = "disabled";
			};
		};

		qcom,msm-imem@146bf000 {
			compatible = "qcom,msm-imem";
			reg = <0x146bf000 0x1000>;
			ranges = <0x0 0x146bf000 0x1000>;
			#address-cells = <1>;
			#size-cells = <1>;

			pil@94c {
				compatible = "qcom,msm-imem-pil";
				reg = <0x94c 4>;
			};

			mem_dump_table@10 {
				compatible = "qcom,msm-imem-mem_dump_table";
				reg = <0x10 8>;
			};
		};

		mem_dump {
			compatible = "qcom,mem-dump";
			memory-region = <&dump_mem>;

			rpmh {
				qcom,dump-size = <0x2000000>;
				qcom,dump-id = <0xec>;
			};

			fcm {
				qcom,dump-size = <0x8400>;
				qcom,dump-id = <0xee>;
			};

			rpm_sw {
				qcom,dump-size = <0x28000>;
				qcom,dump-id = <0xea>;
			};

			pmic {
				qcom,dump-size = <0x10000>;
				qcom,dump-id = <0xe4>;
			};

			tmc_etf {
				qcom,dump-size = <0x10000>;
				qcom,dump-id = <0xf0>;
			};

			tmc_etfswao {
				qcom,dump-size = <0x8400>;
				qcom,dump-id = <0xf1>;
			};

			tmc_etr_reg {
				qcom,dump-size = <0x1000>;
				qcom,dump-id = <0x100>;
			};

			tmc_etf_reg {
				qcom,dump-size = <0x1000>;
				qcom,dump-id = <0x101>;
			};

			etfswao_reg {
				qcom,dump-size = <0x1000>;
				qcom,dump-id = <0x102>;
			};

			misc_data {
				qcom,dump-size = <0x1000>;
				qcom,dump-id = <0xe8>;
			};

			tpdm_swao {
				qcom,dump-size = <0x512>;
				qcom,dump-id = <0xf2>;
			};
		};

		dcc: dcc_v2@10a2000 {
			compatible = "qcom,dcc-v2";
			reg = <0x10a2000 0x1000>,
			      <0x10ae000 0x2000>;
			reg-names = "dcc-base", "dcc-ram-base";

			dcc-ram-offset = <0x6000>;

			qcom,curr-link-list = <2>;
			qcom,link-list = <DCC_READ 0x1740300 6 0>,
					 <DCC_READ 0x1620500 4 0>,
					 <DCC_READ 0x7840000 1 0>,
					 <DCC_READ 0x7841010 12 0>,
					 <DCC_READ 0x7842000 16 0>,
					 <DCC_READ 0x7842500 2 0>,
					 <DCC_LOOP 7 0 0>,
					 <DCC_READ 0x7841000 1 0>,
					 <DCC_LOOP 1 0 0>,
					 <DCC_LOOP 165 0 0>,
					 <DCC_READ 0x7841008 2 0>,
					 <DCC_LOOP 1 0 0>,
					 <DCC_READ 0x17dc3a84 2 0>,
					 <DCC_READ 0x17db3a84 1 0>,
					 <DCC_READ 0x1301000 2 0>,
					 <DCC_READ 0x17990044 1 0>,
					 <DCC_READ 0x17d45f00 1 0>,
					 <DCC_READ 0x17d45f08 6 0>,
					 <DCC_READ 0x17d45f80 1 0>,
					 <DCC_READ 0x17d47418 1 0>,
					 <DCC_READ 0x17d47570 1 0>,
					 <DCC_READ 0x17d47588 1 0>,
					 <DCC_READ 0x17d43700 1 0>,
					 <DCC_READ 0x17d43708 6 0>,
					 <DCC_READ 0x17d43780 1 0>,
					 <DCC_READ 0x17d44c18 1 0>,
					 <DCC_READ 0x17d44d70 1 0>,
					 <DCC_READ 0x17d44d88 1 0>,
					 <DCC_READ 0x17d41700 1 0>,
					 <DCC_READ 0x17d41708 6 0>,
					 <DCC_READ 0x17d41780 1 0>,
					 <DCC_READ 0x17d42c18 1 0>,
					 <DCC_READ 0x17d42d70 1 0>,
					 <DCC_READ 0x17d42d88 1 0>,
					 <DCC_WRITE 0x69ea00c 0x600007 1>,
					 <DCC_WRITE 0x69ea01c 0x136800 1>,
					 <DCC_READ 0x69ea014 1 1>,
					 <DCC_WRITE 0x69ea01c 0x136810 1>,
					 <DCC_READ 0x69ea014 1 1>,
					 <DCC_WRITE 0x69ea01c 0x136820 1>,
					 <DCC_READ 0x69ea014 1 1>,
					 <DCC_WRITE 0x69ea01c 0x136830 1>,
					 <DCC_READ 0x69ea014 1 1>,
					 <DCC_WRITE 0x69ea01c 0x136840 1>,
					 <DCC_READ 0x69ea014 1 1>,
					 <DCC_WRITE 0x69ea01c 0x136850 1>,
					 <DCC_READ 0x69ea014 1 1>,
					 <DCC_WRITE 0x69ea01c 0x136860 1>,
					 <DCC_READ 0x69ea014 1 1>,
					 <DCC_WRITE 0x69ea01c 0x136870 1>,
					 <DCC_READ 0x69ea014 1 1>,
					 <DCC_WRITE 0x069ea01C 0x0003e9a0 1>,
					 <DCC_WRITE 0x069ea01C 0x001368a0 1>,
					 <DCC_READ 0x069ea014 1 1>,
					 <DCC_WRITE 0x069ea01c 0x0003c0a0 1>,
					 <DCC_WRITE 0x069ea01c 0x001368a0 1>,
					 <DCC_READ 0x069ea014 1 1>,
					 <DCC_WRITE 0x069ea01c 0x0003d1a0 1>,
					 <DCC_WRITE 0x069ea01C 0x001368a0 1>,
					 <DCC_READ 0x069ea014 1 1>,
					 <DCC_WRITE 0x069ea01c 0x0003d2a0 1>,
					 <DCC_WRITE 0x069ea01c 0x001368a0 1>,
					 <DCC_READ 0x069ea014 1 1>,
					 <DCC_WRITE 0x069ea01C 0x0003d5a0 1>,
					 <DCC_WRITE 0x069ea01C 0x001368a0 1>,
					 <DCC_READ 0x069ea014 1 1>,
					 <DCC_WRITE 0x069ea01C 0x0003d6a0 1>,
					 <DCC_WRITE 0x069ea01C 0x001368a0 1>,
					 <DCC_READ 0x069ea014 1 1>,
					 <DCC_WRITE 0x069ea01c 0x001368a0 1>,
					 <DCC_WRITE 0x069ea01c 0x001368a0 1>,
					 <DCC_READ 0x069ea014 1 1>,
					 <DCC_WRITE 0x069ea01c 0x0003b1a0 1>,
					 <DCC_WRITE 0x069ea01c 0x001368a0 1>,
					 <DCC_READ 0x069ea014 1 1>,
					 <DCC_WRITE 0x069ea01c 0x0003b2a0 1>,
					 <DCC_WRITE 0x069ea01c 0x001368a0 1>,
					 <DCC_READ 0x069ea014 1 1>,
					 <DCC_WRITE 0x069ea01c 0x0003b5a0 1>,
					 <DCC_WRITE 0x069ea01c 0x001368a0 1>,
					 <DCC_READ 0x069ea014 1 1>,
					 <DCC_WRITE 0x069ea01c 0x0003b6a0 1>,
					 <DCC_WRITE 0x069ea01c 0x001368a0 1>,
					 <DCC_READ 0x069ea014 1 1>,
					 <DCC_WRITE 0x069ea01c 0x0003c2a0 1>,
					 <DCC_WRITE 0x069ea01c 0x001368a0 1>,
					 <DCC_READ 0x069ea014 1 1>,
					 <DCC_WRITE 0x069ea01c 0x0003c5a0 1>,
					 <DCC_WRITE 0x069ea01c 0x001368a0 1>,
					 <DCC_READ 0x069ea014 1 1>,
					 <DCC_WRITE 0x069ea01c 0x0003c6a0 1>,
					 <DCC_WRITE 0x069ea01c 0x001368a0 1>,
					 <DCC_READ 0x069ea014 1 1>,
					 <DCC_WRITE 0x069ea01c 0x00f1e000 1>,
					 <DCC_WRITE 0x069ea008 0x00000007 1>,
					 <DCC_READ 0x013e7e00 31 0>,
					 <DCC_READ 0x01132100 1 0>,
					 <DCC_READ 0x01136044 4 0>,
					 <DCC_READ 0x011360b0 1 0>,
					 <DCC_READ 0x0113e030 2 0>,
					 <DCC_READ 0x01141000 1 0>,
					 <DCC_READ 0x01142028 1 0>,
					 <DCC_READ 0x01148058 4 0>,
					 <DCC_READ 0x01160410 3 0>,
					 <DCC_READ 0x011604a0 1 0>,
					 <DCC_READ 0x011604b8 1 0>,
					 <DCC_READ 0x01165804 1 0>,
					 <DCC_READ 0x01166418 1 0>,
					 <DCC_READ 0x011b2100 1 0>,
					 <DCC_READ 0x011b6044 4 0>,
					 <DCC_READ 0x011be030 2 0>,
					 <DCC_READ 0x011c1000 1 0>,
					 <DCC_READ 0x011c2028 1 0>,
					 <DCC_READ 0x011c8058 4 0>,
					 <DCC_READ 0x011e0410 3 0>,
					 <DCC_READ 0x011e04a0 1 0>,
					 <DCC_READ 0x011e04b8 1 0>,
					 <DCC_READ 0x011e5804 1 0>,
					 <DCC_READ 0x011e6418 1 0>,
					 <DCC_READ 0x01232100 1 0>,
					 <DCC_READ 0x01236044 4 0>,
					 <DCC_READ 0x012360B0 1 0>,
					 <DCC_READ 0x0123E030 2 0>,
					 <DCC_READ 0x01241000 1 0>,
					 <DCC_READ 0x01242028 1 0>,
					 <DCC_READ 0x01248058 4 0>,
					 <DCC_READ 0x01260410 3 0>,
					 <DCC_READ 0x012604a0 1 0>,
					 <DCC_READ 0x012604b8 1 0>,
					 <DCC_READ 0x01265804 1 0>,
					 <DCC_READ 0x01266418 1 0>,
					 <DCC_READ 0x012b2100 1 0>,
					 <DCC_READ 0x012b6044 3 0>,
					 <DCC_READ 0x012b6050 1 0>,
					 <DCC_READ 0x012b60b0 1 0>,
					 <DCC_READ 0x012be030 2 0>,
					 <DCC_READ 0x012c1000 1 0>,
					 <DCC_READ 0x012c2028 1 0>,
					 <DCC_READ 0x012c8058 4 0>,
					 <DCC_READ 0x012e0410 3 0>,
					 <DCC_READ 0x012e04a0 1 0>,
					 <DCC_READ 0x012e04b8 1 0>,
					 <DCC_READ 0x012e5804 1 0>,
					 <DCC_READ 0x012e6418 1 0>,
					 <DCC_READ 0x01380900 8 0>,
					 <DCC_READ 0x01380d00 5 0>,
					 <DCC_READ 0x01350110 4 0>,
					 <DCC_READ 0x01430280 1 0>,
					 <DCC_READ 0x01430288 1 0>,
					 <DCC_READ 0x0143028c 7 0>,
					 <DCC_READ 0x01132100 1 0>,
					 <DCC_READ 0x01136044 4 0>,
					 <DCC_READ 0x011360b0 1 0>,
					 <DCC_READ 0x0113e030 2 0>,
					 <DCC_READ 0x01141000 1 0>,
					 <DCC_READ 0x01142028 1 0>,
					 <DCC_READ 0x01148058 4 0>,
					 <DCC_READ 0x01160410 3 0>,
					 <DCC_READ 0x011604a0 1 0>,
					 <DCC_READ 0x011604b8 1 0>,
					 <DCC_READ 0x01165804 1 0>,
					 <DCC_READ 0x01166418 1 0>,
					 <DCC_READ 0x011b2100 1 0>,
					 <DCC_READ 0x011b6044 4 0>,
					 <DCC_READ 0x011be030 2 0>,
					 <DCC_READ 0x011c1000 1 0>,
					 <DCC_READ 0x011c2028 1 0>,
					 <DCC_READ 0x011c8058 4 0>,
					 <DCC_READ 0x011e0410 3 0>,
					 <DCC_READ 0x011e04a0 1 0>,
					 <DCC_READ 0x011e04b8 1 0>,
					 <DCC_READ 0x011e5804 1 0>,
					 <DCC_READ 0x011e6418 1 0>,
					 <DCC_READ 0x01232100 1 0>,
					 <DCC_READ 0x01236044 4 0>,
					 <DCC_READ 0x012360b0 1 0>,
					 <DCC_READ 0x0123e030 2 0>,
					 <DCC_READ 0x01241000 1 0>,
					 <DCC_READ 0x01242028 1 0>,
					 <DCC_READ 0x01248058 4 0>,
					 <DCC_READ 0x01260410 3 0>,
					 <DCC_READ 0x012604a0 1 0>,
					 <DCC_READ 0x012604b8 1 0>,
					 <DCC_READ 0x01265804 1 0>,
					 <DCC_READ 0x01266418 1 0>,
					 <DCC_READ 0x012b2100 1 0>,
					 <DCC_READ 0x012b6044 3 0>,
					 <DCC_READ 0x012b6050 1 0>,
					 <DCC_READ 0x012b60b0 1 0>,
					 <DCC_READ 0x012be030 2 0>,
					 <DCC_READ 0x012C1000 1 0>,
					 <DCC_READ 0x012C2028 1 0>,
					 <DCC_READ 0x012C8058 4 0>,
					 <DCC_READ 0x012e0410 3 0>,
					 <DCC_READ 0x012e04a0 1 0>,
					 <DCC_READ 0x012e04b8 1 0>,
					 <DCC_READ 0x012e5804 1 0>,
					 <DCC_READ 0x012e6418 1 0>,
					 <DCC_READ 0x01380900 8 0>,
					 <DCC_READ 0x01380d00 5 0>,
					 <DCC_READ 0x01350110 4 0>,
					 <DCC_READ 0x01430280 1 0>,
					 <DCC_READ 0x01430288 1 0>,
					 <DCC_READ 0x0143028c 7 0>,
					 <DCC_READ 0x0c201244 1 0>,
					 <DCC_READ 0x0c202244 1 0>;
		};

		armv8-cpu-erp {
			compatible = "arm,armv8-cpu-erp";
			interrupts = <1 6 4>,
				     <0 35 4>;

			interrupt-names = "l1-l2-irq",
					  "l3-scu-irq";
		};

		cache-controller@1100000 {
			compatible = "qcom,sdm845-llcc";
			reg = <0x1100000 0x200000>, <0x1300000 0x50000> ;
			reg-names = "llcc_base", "llcc_broadcast_base";
			interrupts = <GIC_SPI 582 IRQ_TYPE_LEVEL_HIGH>;
		};

		ufshc1: ufshc@1d84000 {
			compatible = "qcom,sdm845-ufshc", "qcom,ufshc",
				     "jedec,ufs-2.0";
			reg = <0x1d84000 0x2500>;
			interrupts = <GIC_SPI 265 IRQ_TYPE_LEVEL_HIGH>;
			phys = <&ufsphy1_lanes>;
			phy-names = "ufsphy";
			lanes-per-direction = <2>;
			power-domains = <&gcc UFS_PHY_GDSC>;

			clock-names =
				"core_clk",
				"bus_aggr_clk",
				"iface_clk",
				"core_clk_unipro",
				"ref_clk",
				"tx_lane0_sync_clk",
				"rx_lane0_sync_clk",
				"rx_lane1_sync_clk";
			clocks =
				<&gcc GCC_UFS_PHY_AXI_CLK>,
				<&gcc GCC_AGGRE_UFS_PHY_AXI_CLK>,
				<&gcc GCC_UFS_PHY_AHB_CLK>,
				<&gcc GCC_UFS_PHY_UNIPRO_CORE_CLK>,
				<&rpmhcc RPMH_CXO_CLK>,
				<&gcc GCC_UFS_PHY_TX_SYMBOL_0_CLK>,
				<&gcc GCC_UFS_PHY_RX_SYMBOL_0_CLK>,
				<&gcc GCC_UFS_PHY_RX_SYMBOL_1_CLK>;
			freq-table-hz =
				<50000000 200000000>,
				<0 0>,
				<0 0>,
				<37500000 150000000>,
				<0 0>,
				<0 0>,
				<0 0>,
				<0 0>;

			interconnects = <&qnoc 53 &qnoc 512>,
					<&qnoc 1 &qnoc 554>;
			interconnect-names = "ufs-ddr", "cpu-ufs";

			qcom,msm-bus,name = "ufshc_mem";
			qcom,msm-bus,num-cases = <22>;
			qcom,msm-bus,num-paths = <2>;
			qcom,msm-bus,vectors-KBps =
			/*
			* During HS G3 UFS runs at nominal voltage corner, vote
			* higher bandwidth to push other buses in the data path
			* to run at nominal to achieve max throughput.
			* 4GBps pushes BIMC to run at nominal.
			* 200MBps pushes CNOC to run at nominal.
			* Vote for half of this bandwidth for HS G3 1-lane.
			* For max bandwidth, vote high enough to push the buses
			* to run in turbo voltage corner.
			*/
			<0 0>, <0 0>,          /* No vote */
			<922 0>, <1000 0>,     /* PWM G1 */
			<1844 0>, <1000 0>,    /* PWM G2 */
			<3688 0>, <1000 0>,    /* PWM G3 */
			<7376 0>, <1000 0>,    /* PWM G4 */
			<1844 0>, <1000 0>,    /* PWM G1 L2 */
			<3688 0>, <1000 0>,    /* PWM G2 L2 */
			<7376 0>, <1000 0>,    /* PWM G3 L2 */
			<14752 0>, <1000 0>,   /* PWM G4 L2 */
			<127796 0>, <1000 0>,  /* HS G1 RA */
			<255591 0>, <1000 0>,  /* HS G2 RA */
			<2097152 0>, <102400 0>,  /* HS G3 RA */
			<255591 0>, <1000 0>,  /* HS G1 RA L2 */
			<511181 0>, <1000 0>,  /* HS G2 RA L2 */
			<4194304 0>, <204800 0>, /* HS G3 RA L2 */
			<149422 0>, <1000 0>,  /* HS G1 RB */
			<298189 0>, <1000 0>,  /* HS G2 RB */
			<2097152 0>, <102400 0>,  /* HS G3 RB */
			<298189 0>, <1000 0>,  /* HS G1 RB L2 */
			<596378 0>, <1000 0>,  /* HS G2 RB L2 */
			/* As UFS working in HS G3 RB L2 mode, aggregated
			* bandwidth (AB) should take care of providing
			* optimum throughput requested. However, as tested,
			* in order to scale up CNOC clock, instantaneous
			* bindwidth (IB) needs to be given a proper value too.
			*/
			<4194304 0>, <204800 409600>, /* HS G3 RB L2 */
			<7643136 0>, <307200 0>; /* Max. bandwidth */

			qcom,bus-vector-names = "MIN",
			"PWM_G1_L1", "PWM_G2_L1", "PWM_G3_L1", "PWM_G4_L1",
			"PWM_G1_L2", "PWM_G2_L2", "PWM_G3_L2", "PWM_G4_L2",
			"HS_RA_G1_L1", "HS_RA_G2_L1", "HS_RA_G3_L1",
			"HS_RA_G1_L2", "HS_RA_G2_L2", "HS_RA_G3_L2",
			"HS_RB_G1_L1", "HS_RB_G2_L1", "HS_RB_G3_L1",
			"HS_RB_G1_L2", "HS_RB_G2_L2", "HS_RB_G3_L2",
			"MAX";

			resets = <&gcc GCC_UFS_PHY_BCR>;
			reset-names = "rst";

			status = "disabled";
		};

		ufsphy1: phy@1d87000 {
			compatible = "qcom,sdm845-qmp-ufs-phy";
			reg = <0x1d87000 0x18c>;
			#address-cells = <1>;
			#size-cells = <1>;
			ranges;
			clock-names = "ref",
				      "ref_aux";
			clocks = <&gcc GCC_UFS_MEM_CLKREF_CLK>,
				 <&gcc GCC_UFS_PHY_PHY_AUX_CLK>;

			status = "disabled";

			ufsphy1_lanes: lanes@1d87400 {
				reg = <0x1d87400 0x108>,
				      <0x1d87600 0x1e0>,
				      <0x1d87c00 0x1dc>,
				      <0x1d87800 0x108>,
				      <0x1d87a00 0x1e0>;
				#phy-cells = <0>;
			};
		};

		ipa_hw: ipa@1e00000 {
			compatible = "qcom,ipa";

			qcom,ipa-hw-ver = <QCOM_IPA_HW_VER_v3_5_1>;
			qcom,ee = <0>;

			reg = <0x1e00000 0x34000>,
			      <0x1e04000 0x2c000>;
			reg-names = "ipa-base",
				    "gsi-base";

			interrupts-extended =
				<&intc GIC_SPI 311 IRQ_TYPE_EDGE_RISING>,
				<&intc GIC_SPI 432 IRQ_TYPE_LEVEL_HIGH>,
				<&ipa_smp2p_in 0 IRQ_TYPE_EDGE_RISING>,
				<&ipa_smp2p_in 1 IRQ_TYPE_EDGE_RISING>;
			interrupt-names = "ipa-irq",
					  "gsi-irq",
					  "ipa-clock-query",
					  "ipa-post-init";

			qcom,smem-states = <&ipa_smp2p_out 0>,
					   <&ipa_smp2p_out 1>;
			qcom,smem-state-names = "ipa-clock-enabled-valid",
						"ipa-clock-enabled";
		};

		tcsr_mutex_regs: syscon@1f40000 {
			compatible = "syscon";
			reg = <0x1f40000 0x40000>;
		};

		tcsr: syscon@1fc0000 {
			compatible = "syscon";
			reg = <0x1fc0000 0x30000>;
		};

		tlmm: pinctrl@3400000 {
			compatible = "qcom,sdm845-pinctrl";
			reg = <0x03400000 0xc00000>;
			gpio-controller;
			#gpio-cells = <2>;
			interrupt-controller;
			#interrupt-cells = <2>;
			interrupts-extended =
				<&intc GIC_SPI 208 IRQ_TYPE_LEVEL_HIGH>,
				<&pdc 30 IRQ_TYPE_LEVEL_HIGH>,
				<&pdc 31 IRQ_TYPE_LEVEL_HIGH>,
				<&pdc 32 IRQ_TYPE_LEVEL_HIGH>,
				<&pdc 33 IRQ_TYPE_LEVEL_HIGH>,
				<&pdc 34 IRQ_TYPE_LEVEL_HIGH>,
				<&pdc 35 IRQ_TYPE_LEVEL_HIGH>,
				<&pdc 36 IRQ_TYPE_LEVEL_HIGH>,
				<&pdc 37 IRQ_TYPE_LEVEL_HIGH>,
				<&pdc 38 IRQ_TYPE_LEVEL_HIGH>,
				<&pdc 39 IRQ_TYPE_LEVEL_HIGH>,
				<&pdc 117 IRQ_TYPE_LEVEL_HIGH>,
				<&pdc 41 IRQ_TYPE_LEVEL_HIGH>,
				<&pdc 42 IRQ_TYPE_LEVEL_HIGH>,
				<&pdc 43 IRQ_TYPE_LEVEL_HIGH>,
				<&pdc 44 IRQ_TYPE_LEVEL_HIGH>,
				<&pdc 45 IRQ_TYPE_LEVEL_HIGH>,
				<&pdc 46 IRQ_TYPE_LEVEL_HIGH>,
				<&pdc 47 IRQ_TYPE_LEVEL_HIGH>,
				<&pdc 115 IRQ_TYPE_LEVEL_HIGH>,
				<&pdc 49 IRQ_TYPE_LEVEL_HIGH>,
				<&pdc 50 IRQ_TYPE_LEVEL_HIGH>,
				<&pdc 51 IRQ_TYPE_LEVEL_HIGH>,
				<&pdc 52 IRQ_TYPE_LEVEL_HIGH>,
				<&pdc 118 IRQ_TYPE_LEVEL_HIGH>,
				<&pdc 54 IRQ_TYPE_LEVEL_HIGH>,
				<&pdc 55 IRQ_TYPE_LEVEL_HIGH>,
				<&pdc 56 IRQ_TYPE_LEVEL_HIGH>,
				<&pdc 57 IRQ_TYPE_LEVEL_HIGH>,
				<&pdc 58 IRQ_TYPE_LEVEL_HIGH>,
				<&pdc 59 IRQ_TYPE_LEVEL_HIGH>,
				<&pdc 60 IRQ_TYPE_LEVEL_HIGH>,
				<&pdc 61 IRQ_TYPE_LEVEL_HIGH>,
				<&pdc 62 IRQ_TYPE_LEVEL_HIGH>,
				<&pdc 63 IRQ_TYPE_LEVEL_HIGH>,
				<&pdc 64 IRQ_TYPE_LEVEL_HIGH>,
				<&pdc 65 IRQ_TYPE_LEVEL_HIGH>,
				<&pdc 66 IRQ_TYPE_LEVEL_HIGH>,
				<&pdc 67 IRQ_TYPE_LEVEL_HIGH>,
				<&pdc 68 IRQ_TYPE_LEVEL_HIGH>,
				<&pdc 69 IRQ_TYPE_LEVEL_HIGH>,
				<&pdc 70 IRQ_TYPE_LEVEL_HIGH>,
				<&pdc 71 IRQ_TYPE_LEVEL_HIGH>,
				<&pdc 72 IRQ_TYPE_LEVEL_HIGH>,
				<&pdc 73 IRQ_TYPE_LEVEL_HIGH>,
				<&pdc 74 IRQ_TYPE_LEVEL_HIGH>,
				<&pdc 75 IRQ_TYPE_LEVEL_HIGH>,
				<&pdc 76 IRQ_TYPE_LEVEL_HIGH>,
				<&pdc 77 IRQ_TYPE_LEVEL_HIGH>,
				<&pdc 116 IRQ_TYPE_LEVEL_HIGH>,
				<&pdc 79 IRQ_TYPE_LEVEL_HIGH>,
				<&pdc 80 IRQ_TYPE_LEVEL_HIGH>,
				<&pdc 81 IRQ_TYPE_LEVEL_HIGH>,
				<&pdc 82 IRQ_TYPE_LEVEL_HIGH>,
				<&pdc 84 IRQ_TYPE_LEVEL_HIGH>,
				<&pdc 85 IRQ_TYPE_LEVEL_HIGH>,
				<&pdc 86 IRQ_TYPE_LEVEL_HIGH>,
				<&pdc 90 IRQ_TYPE_LEVEL_HIGH>,
				<&pdc 91 IRQ_TYPE_LEVEL_HIGH>,
				<&pdc 92 IRQ_TYPE_LEVEL_HIGH>,
				<&pdc 93 IRQ_TYPE_LEVEL_HIGH>,
				<&pdc 94 IRQ_TYPE_LEVEL_HIGH>,
				<&pdc 95 IRQ_TYPE_LEVEL_HIGH>,
				<&pdc 96 IRQ_TYPE_LEVEL_HIGH>,
				<&pdc 97 IRQ_TYPE_LEVEL_HIGH>,
				<&pdc 98 IRQ_TYPE_LEVEL_HIGH>,
				<&pdc 99 IRQ_TYPE_LEVEL_HIGH>,
				<&pdc 100 IRQ_TYPE_LEVEL_HIGH>,
				<&pdc 102 IRQ_TYPE_LEVEL_HIGH>,
				<&pdc 103 IRQ_TYPE_LEVEL_HIGH>,
				<&pdc 104 IRQ_TYPE_LEVEL_HIGH>,
				<&pdc 105 IRQ_TYPE_LEVEL_HIGH>,
				<&pdc 106 IRQ_TYPE_LEVEL_HIGH>,
				<&pdc 107 IRQ_TYPE_LEVEL_HIGH>,
				<&pdc 108 IRQ_TYPE_LEVEL_HIGH>;
			interrupt-names = "summary-irq",
				"gpio1",
				"gpio3",
				"gpio5",
				"gpio10",
				"gpio11",
				"gpio20",
				"gpio22",
				"gpio24",
				"gpio26",
				"gpio30",
				"gpio31",
				"gpio32",
				"gpio34",
				"gpio36",
				"gpio37",
				"gpio38",
				"gpio39",
				"gpio40",
				"gpio41",
				"gpio43",
				"gpio44",
				"gpio46",
				"gpio48",
				"gpio49",
				"gpio52",
				"gpio53",
				"gpio54",
				"gpio56",
				"gpio57",
				"gpio58",
				"gpio59",
				"gpio60",
				"gpio61",
				"gpio62",
				"gpio63",
				"gpio64",
				"gpio66",
				"gpio68",
				"gpio71",
				"gpio73",
				"gpio77",
				"gpio78",
				"gpio79",
				"gpio80",
				"gpio84",
				"gpio85",
				"gpio86",
				"gpio88",
				"gpio89",
				"gpio91",
				"gpio92",
				"gpio95",
				"gpio96",
				"gpio101",
				"gpio103",
				"gpio104",
				"gpio115",
				"gpio116",
				"gpio117",
				"gpio118",
				"gpio119",
				"gpio120",
				"gpio121",
				"gpio122",
				"gpio123",
				"gpio124",
				"gpio125",
				"gpio127",
				"gpio128",
				"gpio129",
				"gpio130",
				"gpio132",
				"gpio133",
				"gpio145";

			dpu_dp_aux_active: dpu-dp-aux_active {
				pinmux {
					pins = "gpio43", "gpio51";
					function = "gpio";
				};

				/* TODO: move pinconf to board file */
				pinconf {
					pins = "gpio43", "gpio51";
					bias-disable;
					drive-strength = <8>;
				};
			};

			dpu_dp_aux_suspend: dpu-dp-aux-suspend {
				pinmux {
					pins = "gpio43", "gpio51";
					function = "gpio";
				};

				/* TODO: move pinconf to board file */
				pinconf {
					pins = "gpio43", "gpio51";
					bias-pull-down;
					drive-strength = <2>;
				};
			};

			dpu_dp_usbplug_cc_active: dpu-dp-usbplug-cc-active {
				pinmux {
					pins = "gpio38";
					function = "gpio";
				};

				/* TODO: move pinconf to board file */
				pinconf {
					pins = "gpio38";
					bias-disable;
					drive-strength = <16>;
				};
			};

			dpu_dp_usbplug_cc_suspend: dpu-dp-usbplug-cc-suspend {
				pinmux {
					pins = "gpio38";
					function = "gpio";
				};

				/* TODO: move pinconf to board file */
				pinconf {
					pins = "gpio38";
					bias-pull-down;
					drive-strength = <2>;
				};
			};

			dpu_dsi_active: dpu-dsi-active {
				pinmux {
					pins = "gpio6", "gpio52";
					function = "gpio";
				};

				/* TODO: move pinconf to board file */
				pinconf {
					pins = "gpio6", "gpio52";
					drive-strength = <8>;
					/*bias-pull-up; */
					bias-disable;
				};
			};
			dpu_dsi_suspend: dpu-dsi-suspend {
				pinmux {
					pins = "gpio6", "gpio52";
					function = "gpio";
				};

				/* TODO: move pinconf to board file */
				pinconf {
					pins = "gpio6", "gpio52";
					drive-strength = <2>;
					bias-pull-down;
				};
			};

			dpu_te_active: dpu-te-active {
				pinmux {
					pins = "gpio10";
					function = "mdp_vsync";
				};

				/* TODO: move pinconf to board file */
				pinconf {
					pins = "gpio10";
					drive-strength = <2>;
					bias-pull-down;
				};
			};

			dpu_te_suspend: dpu-te-suspend {
				pinmux {
					pins = "gpio10";
					function = "mdp_vsync";
				};

				/* TODO: move pinconf to board file */
				pinconf {
					pins = "gpio10";
					drive-strength = <2>;
					bias-pull-down;
				};
			};

			qspi_clk: qspi-clk {
				pinmux {
					pins = "gpio95";
					function = "qspi_clk";
				};
			};

			qspi_cs0: qspi-cs0 {
				pinmux {
					pins = "gpio90";
					function = "qspi_cs";
				};
			};

			qspi_cs1: qspi-cs1 {
				pinmux {
					pins = "gpio89";
					function = "qspi_cs";
				};
			};

			qspi_data01: qspi-data01 {
				pinmux-data {
					pins = "gpio91", "gpio92";
					function = "qspi_data";
				};
			};

			qspi_data12: qspi-data12 {
				pinmux-data {
					pins = "gpio93", "gpio94";
					function = "qspi_data";
				};
			};

			qup_i2c0_default: qup-i2c0-default {
				pinmux {
					pins = "gpio0", "gpio1";
					function = "qup0";
				};
			};

			qup_i2c1_default: qup-i2c1-default {
				pinmux {
					pins = "gpio17", "gpio18";
					function = "qup1";
				};
			};

			qup_i2c2_default: qup-i2c2-default {
				pinmux {
					pins = "gpio27", "gpio28";
					function = "qup2";
				};
			};

			qup_i2c3_default: qup-i2c3-default {
				pinmux {
					pins = "gpio41", "gpio42";
					function = "qup3";
				};
			};

			qup_i2c4_default: qup-i2c4-default {
				pinmux {
					pins = "gpio89", "gpio90";
					function = "qup4";
				};
			};

			qup_i2c5_default: qup-i2c5-default {
				pinmux {
					pins = "gpio85", "gpio86";
					function = "qup5";
				};
			};

			qup_i2c6_default: qup-i2c6-default {
				pinmux {
					pins = "gpio45", "gpio46";
					function = "qup6";
				};
			};

			qup_i2c7_default: qup-i2c7-default {
				pinmux {
					pins = "gpio93", "gpio94";
					function = "qup7";
				};
			};

			qup_i2c8_default: qup-i2c8-default {
				pinmux {
					pins = "gpio65", "gpio66";
					function = "qup8";
				};
			};

			qup_i2c9_default: qup-i2c9-default {
				pinmux {
					pins = "gpio6", "gpio7";
					function = "qup9";
				};
			};

			qup_i2c10_default: qup-i2c10-default {
				pinmux {
					pins = "gpio55", "gpio56";
					function = "qup10";
				};
			};

			qup_i2c11_default: qup-i2c11-default {
				pinmux {
					pins = "gpio31", "gpio32";
					function = "qup11";
				};
			};

			qup_i2c12_default: qup-i2c12-default {
				pinmux {
					pins = "gpio49", "gpio50";
					function = "qup12";
				};

				pinconf {
					pins = "gpio49", "gpio50";
					drive-strength = <2>;
					bias-disable;
				};
			};

			qup_i2c13_default: qup-i2c13-default {
				pinmux {
					pins = "gpio105", "gpio106";
					function = "qup13";
				};
			};

			qup_i2c14_default: qup-i2c14-default {
				pinmux {
					pins = "gpio33", "gpio34";
					function = "qup14";
				};
			};

			qup_i2c15_default: qup-i2c15-default {
				pinmux {
					pins = "gpio81", "gpio82";
					function = "qup15";
				};
			};

			qup_spi0_default: qup-spi0-default {
				pinmux {
					pins = "gpio0", "gpio1",
					       "gpio2", "gpio3";
					function = "qup0";
				};
			};

			qup_spi1_default: qup-spi1-default {
				pinmux {
					pins = "gpio17", "gpio18",
					       "gpio19", "gpio20";
					function = "qup1";
				};
			};

			qup_spi2_default: qup-spi2-default {
				pinmux {
					pins = "gpio27", "gpio28",
					       "gpio29", "gpio30";
					function = "qup2";
				};
			};

			qup_spi3_default: qup-spi3-default {
				pinmux {
					pins = "gpio41", "gpio42",
					       "gpio43", "gpio44";
					function = "qup3";
				};
			};

			qup_spi4_default: qup-spi4-default {
				pinmux {
					pins = "gpio89", "gpio90",
					       "gpio91", "gpio92";
					function = "qup4";
				};
			};

			qup_spi5_default: qup-spi5-default {
				pinmux {
					pins = "gpio85", "gpio86",
					       "gpio87", "gpio88";
					function = "qup5";
				};
			};

			qup_spi6_default: qup-spi6-default {
				pinmux {
					pins = "gpio45", "gpio46",
					       "gpio47", "gpio48";
					function = "qup6";
				};
			};

			qup_spi7_default: qup-spi7-default {
				pinmux {
					pins = "gpio93", "gpio94",
					       "gpio95", "gpio96";
					function = "qup7";
				};
			};

			qup_spi8_default: qup-spi8-default {
				pinmux {
					pins = "gpio65", "gpio66",
					       "gpio67", "gpio68";
					function = "qup8";
				};
			};

			qup_spi9_default: qup-spi9-default {
				pinmux {
					pins = "gpio6", "gpio7",
					       "gpio4", "gpio5";
					function = "qup9";
				};
			};

			qup_spi10_default: qup-spi10-default {
				pinmux {
					pins = "gpio55", "gpio56",
					       "gpio53", "gpio54";
					function = "qup10";
				};
			};

			qup_spi11_default: qup-spi11-default {
				pinmux {
					pins = "gpio31", "gpio32",
					       "gpio33", "gpio34";
					function = "qup11";
				};
			};

			qup_spi12_default: qup-spi12-default {
				pinmux {
					pins = "gpio49", "gpio50",
					       "gpio51", "gpio52";
					function = "qup12";
				};
			};

			qup_spi13_default: qup-spi13-default {
				pinmux {
					pins = "gpio105", "gpio106",
					       "gpio107", "gpio108";
					function = "qup13";
				};
			};

			qup_spi14_default: qup-spi14-default {
				pinmux {
					pins = "gpio33", "gpio34",
					       "gpio31", "gpio32";
					function = "qup14";
				};
			};

			qup_spi15_default: qup-spi15-default {
				pinmux {
					pins = "gpio81", "gpio82",
					       "gpio83", "gpio84";
					function = "qup15";
				};
			};

			qup_uart0_default: qup-uart0-default {
				pinmux {
					pins = "gpio2", "gpio3";
					function = "qup0";
				};
			};

			qup_uart1_default: qup-uart1-default {
				pinmux {
					pins = "gpio19", "gpio20";
					function = "qup1";
				};
			};

			qup_uart2_default: qup-uart2-default {
				pinmux {
					pins = "gpio29", "gpio30";
					function = "qup2";
				};
			};

			qup_uart3_default: qup-uart3-default {
				pinmux {
					pins = "gpio43", "gpio44";
					function = "qup3";
				};
			};

			qup_uart4_default: qup-uart4-default {
				pinmux {
					pins = "gpio91", "gpio92";
					function = "qup4";
				};
			};

			qup_uart5_default: qup-uart5-default {
				pinmux {
					pins = "gpio87", "gpio88";
					function = "qup5";
				};
			};

			qup_uart6_default: qup-uart6-default {
				pinmux {
					pins = "gpio47", "gpio48";
					function = "qup6";
				};
			};

			qup_uart7_default: qup-uart7-default {
				pinmux {
					pins = "gpio95", "gpio96";
					function = "qup7";
				};
			};

			qup_uart8_default: qup-uart8-default {
				pinmux {
					pins = "gpio67", "gpio68";
					function = "qup8";
				};
			};

			qup_uart9_default: qup-uart9-default {
				pinmux {
					pins = "gpio4", "gpio5";
					function = "qup9";
				};
			};

			qup_uart10_default: qup-uart10-default {
				pinmux {
					pins = "gpio53", "gpio54";
					function = "qup10";
				};
			};

			qup_uart11_default: qup-uart11-default {
				pinmux {
					pins = "gpio33", "gpio34";
					function = "qup11";
				};
			};

			qup_uart12_default: qup-uart12-default {
				pinmux {
					pins = "gpio51", "gpio52";
					function = "qup12";
				};
			};

			qup_uart13_default: qup-uart13-default {
				pinmux {
					pins = "gpio107", "gpio108";
					function = "qup13";
				};
			};

			qup_uart14_default: qup-uart14-default {
				pinmux {
					pins = "gpio31", "gpio32";
					function = "qup14";
				};
			};

			qup_uart15_default: qup-uart15-default {
				pinmux {
					pins = "gpio83", "gpio84";
					function = "qup15";
				};
			};
		};

		modem-pil@4080000 {
			compatible = "qcom,sdm845-mss-pil";
			reg = <0x04080000 0x408>, <0x04180000 0x48>;

			reg-names = "qdsp6", "rmb";

			interrupts-extended =
				<&intc GIC_SPI 266 IRQ_TYPE_EDGE_RISING>,
				<&modem_smp2p_in 0 IRQ_TYPE_EDGE_RISING>,
				<&modem_smp2p_in 1 IRQ_TYPE_EDGE_RISING>,
				<&modem_smp2p_in 2 IRQ_TYPE_EDGE_RISING>,
				<&modem_smp2p_in 3 IRQ_TYPE_EDGE_RISING>;

			interrupt-names = "wdog", "fatal", "ready",
					  "handover", "stop-ack";

			clocks = <&gcc GCC_MSS_CFG_AHB_CLK>,
				 <&gcc GCC_MSS_Q6_MEMNOC_AXI_CLK>,
				 <&gcc GCC_BOOT_ROM_AHB_CLK>,
				 <&gcc GCC_MSS_GPLL0_DIV_CLK_SRC>,
				 <&gcc GCC_MSS_SNOC_AXI_CLK>,
				 <&gcc GCC_MSS_AXIS2_CLK>,
				 <&gcc GCC_MSS_MFAB_AXIS_CLK>,
				 <&gcc GCC_PRNG_AHB_CLK>,
				 <&xo_board>;

			clock-names = "iface", "bus", "mem", "gpll0_mss",
				      "snoc_axi", "axis2", "mnoc_axi",
				      "prng", "xo";

			qcom,smem-states = <&modem_smp2p_out 0>;
			qcom,smem-state-names = "stop";

			resets = <&aoss_reset AOSS_CC_MSS_RESTART>,
				 <&pdc_reset PDC_MODEM_SYNC_RESET>;
			reset-names = "mss_restart", "pdc_reset";

			qcom,halt-regs = <&tcsr_mutex_regs
						0x23000 0x25000 0x24000>;

			power-domains = <&rpmhpd SDM845_CX>, <&rpmhpd SDM845_MX>, <&rpmhpd SDM845_MSS>;
			power-domain-names = "cx", "mx", "mss";

			mba {
				memory-region = <&mba_mem>;
			};

			mpss {
				memory-region = <&mpss_mem>;
			};

			glink-edge {
				interrupts = <0 449 IRQ_TYPE_EDGE_RISING>;
				label = "modem";
				qcom,remote-pid = <1>;
				mboxes = <&apss_shared 12>;
				mbox-names = "mpss_smem";
			};
		};

		gpucc: clock-controller@5090000 {
			compatible = "qcom,sdm845-gpucc";
			reg = <0x5090000 0x9000>;
			#clock-cells = <1>;
			#reset-cells = <1>;
			#power-domain-cells = <1>;
		};

		sdhc_2: sdhci@8804000 {
			compatible = "qcom,sdhci-msm-v5";
			reg = <0x8804000 0x1000>;
			reg-names = "hc_mem";

			interrupts =
				<GIC_SPI 204 IRQ_TYPE_LEVEL_HIGH>,
				<GIC_SPI 222 IRQ_TYPE_LEVEL_HIGH>;
			interrupt-names = "hc_irq", "pwr_irq";

			qcom,bus-width = <4>;
			qcom,large-address-bus;

			qcom,clk-rates = <400000 20000000 25000000
					  50000000 100000000 201500000>;
			qcom,bus-speed-mode = "SDR12", "SDR25", "SDR50",
					      "DDR50", "SDR104";

			clocks = <&gcc GCC_SDCC2_AHB_CLK>,
				 <&gcc GCC_SDCC2_APPS_CLK>;
			clock-names = "iface", "core";

			status = "disabled";
		};

		qcom_rng: qrng@793000 {
			compatible = "qcom,prng-ee";
			reg = <0x793000 0x1000>;
			clocks = <&gcc GCC_PRNG_AHB_CLK>;
			clock-names = "core";
			qcom,no-prng-config;
			interconnect-names = "cpu";
			interconnects = <&qnoc 1 &qnoc 540>;
			qcom,bandwidth-max = <300000>;
		};

		cryptobam: dma@1dc4000 {
			compatible = "qcom,bam-v1.7.0";
			reg = <0x1dc4000 0x24000>;
			interrupts = <0 272 0>;
			clocks = <&gcc GCC_CE1_AHB_CLK>;
			clock-names = "bam_clk";
			#dma-cells = <1>;
			qcom,ee = <0>;
		};

		qce_crypto: crypto@1de0000 {
			compatible = "qcom,crypto-v5.1";
			reg = <0x1dfa000 0x6000>;
			clocks = <&gcc GCC_CE1_AHB_CLK>,
				 <&gcc GCC_CE1_AXI_CLK>,
				 <&gcc GCC_CE1_CLK>;
			clock-names = "iface", "bus", "core";
			dmas = <&cryptobam 4>, <&cryptobam 5>;
			dma-names = "rx", "tx";
			interconnect-names = "gpce";
			interconnects = <&qnoc 35 &qnoc 523>;
			qcom,bandwidth-max = <393600>;
		};

		qspi: spi@88df000 {
			compatible = "qcom,sdm845-qspi", "qcom,qspi-v1";
			reg = <0x88df000 0x600>;
			#address-cells = <1>;
			#size-cells = <0>;
			interrupts = <GIC_SPI 82 IRQ_TYPE_LEVEL_HIGH>;
			clocks = <&gcc GCC_QSPI_CNOC_PERIPH_AHB_CLK>,
				 <&gcc GCC_QSPI_CORE_CLK>;
			clock-names = "iface", "core";
			status = "disabled";
		};

		usb_1_hsphy: phy@88e2000 {
			compatible = "qcom,sdm845-qusb2-phy";
			reg = <0x88e2000 0x400>;
			status = "disabled";
			#phy-cells = <0>;

			clocks = <&gcc GCC_USB_PHY_CFG_AHB2PHY_CLK>,
				 <&rpmhcc RPMH_CXO_CLK>;
			clock-names = "cfg_ahb", "ref";

			resets = <&gcc GCC_QUSB2PHY_PRIM_BCR>;

			nvmem-cells = <&qusb2p_hstx_trim>;
		};

		usb_2_hsphy: phy@88e3000 {
			compatible = "qcom,sdm845-qusb2-phy";
			reg = <0x88e3000 0x400>;
			status = "disabled";
			#phy-cells = <0>;

			clocks = <&gcc GCC_USB_PHY_CFG_AHB2PHY_CLK>,
				 <&rpmhcc RPMH_CXO_CLK>;
			clock-names = "cfg_ahb", "ref";

			resets = <&gcc GCC_QUSB2PHY_SEC_BCR>;

			nvmem-cells = <&qusb2s_hstx_trim>;
		};

		usb_1_qmpphy: phy@88e9000 {
			compatible = "qcom,sdm845-qmp-usb3-phy";
			reg = <0x88e9000 0x18c>,
			      <0x88e8000 0x10>;
			reg-names = "reg-base", "dp_com";
			status = "disabled";
			#clock-cells = <1>;
			#address-cells = <1>;
			#size-cells = <1>;
			ranges;

			clocks = <&gcc GCC_USB3_PRIM_PHY_AUX_CLK>,
				 <&gcc GCC_USB_PHY_CFG_AHB2PHY_CLK>,
				 <&gcc GCC_USB3_PRIM_CLKREF_CLK>,
				 <&gcc GCC_USB3_PRIM_PHY_COM_AUX_CLK>;
			clock-names = "aux", "cfg_ahb", "ref", "com_aux";

			resets = <&gcc GCC_USB3_DP_PHY_PRIM_BCR>,
				 <&gcc GCC_USB3_PHY_PRIM_BCR>;
			reset-names = "phy", "common";

			usb_1_ssphy: lanes@88e9200 {
				reg = <0x88e9200 0x128>,
				      <0x88e9400 0x200>,
				      <0x88e9c00 0x218>,
				      <0x88e9600 0x128>,
				      <0x88e9800 0x200>,
				      <0x88e9a00 0x100>;
				#phy-cells = <0>;
				clocks = <&gcc GCC_USB3_PRIM_PHY_PIPE_CLK>;
				clock-names = "pipe0";
				clock-output-names = "usb3_phy_pipe_clk_src";
			};
		};

		usb_2_qmpphy: phy@88eb000 {
			compatible = "qcom,sdm845-qmp-usb3-uni-phy";
			reg = <0x88eb000 0x18c>;
			status = "disabled";
			#clock-cells = <1>;
			#address-cells = <1>;
			#size-cells = <1>;
			ranges;

			clocks = <&gcc GCC_USB3_SEC_PHY_AUX_CLK>,
				 <&gcc GCC_USB_PHY_CFG_AHB2PHY_CLK>,
				 <&gcc GCC_USB3_SEC_CLKREF_CLK>,
				 <&gcc GCC_USB3_SEC_PHY_COM_AUX_CLK>;
			clock-names = "aux", "cfg_ahb", "ref", "com_aux";

			resets = <&gcc GCC_USB3PHY_PHY_SEC_BCR>,
				 <&gcc GCC_USB3_PHY_SEC_BCR>;
			reset-names = "phy", "common";

			usb_2_ssphy: lane@88eb200 {
				reg = <0x88eb200 0x128>,
				      <0x88eb400 0x1fc>,
				      <0x88eb800 0x218>,
				      <0x88eb600 0x70>;
				#phy-cells = <0>;
				clocks = <&gcc GCC_USB3_SEC_PHY_PIPE_CLK>;
				clock-names = "pipe0";
				clock-output-names = "usb3_uni_phy_pipe_clk_src";
			};
		};

		usb_1: usb@a6f8800 {
			compatible = "qcom,sdm845-dwc3", "qcom,dwc3";
			reg = <0xa6f8800 0x400>;
			status = "disabled";
			#address-cells = <1>;
			#size-cells = <1>;
			ranges;

			clocks = <&gcc GCC_CFG_NOC_USB3_PRIM_AXI_CLK>,
				 <&gcc GCC_USB30_PRIM_MASTER_CLK>,
				 <&gcc GCC_AGGRE_USB3_PRIM_AXI_CLK>,
				 <&gcc GCC_USB30_PRIM_MOCK_UTMI_CLK>,
				 <&gcc GCC_USB30_PRIM_SLEEP_CLK>;
			clock-names = "cfg_noc", "core", "iface", "mock_utmi",
				      "sleep";

			assigned-clocks = <&gcc GCC_USB30_PRIM_MOCK_UTMI_CLK>,
					  <&gcc GCC_USB30_PRIM_MASTER_CLK>;
			assigned-clock-rates = <19200000>, <150000000>;

			interrupts = <GIC_SPI 131 IRQ_TYPE_LEVEL_HIGH>,
				     <GIC_SPI 486 IRQ_TYPE_LEVEL_HIGH>,
				     <GIC_SPI 488 IRQ_TYPE_LEVEL_HIGH>,
				     <GIC_SPI 489 IRQ_TYPE_LEVEL_HIGH>;
			interrupt-names = "hs_phy_irq", "ss_phy_irq",
					  "dm_hs_phy_irq", "dp_hs_phy_irq";

			power-domains = <&gcc USB30_PRIM_GDSC>;

			resets = <&gcc GCC_USB30_PRIM_BCR>;

			usb_1_dwc3: dwc3@a600000 {
				compatible = "snps,dwc3";
				reg = <0xa600000 0xcd00>;
				interrupts = <GIC_SPI 133 IRQ_TYPE_LEVEL_HIGH>;
				snps,dis_u2_susphy_quirk;
				snps,dis_enblslpm_quirk;
				phys = <&usb_1_hsphy>, <&usb_1_ssphy>;
				phy-names = "usb2-phy", "usb3-phy";
			};
		};

		usb_2: usb@a8f8800 {
			compatible = "qcom,sdm845-dwc3", "qcom,dwc3";
			reg = <0xa8f8800 0x400>;
			status = "disabled";
			#address-cells = <1>;
			#size-cells = <1>;
			ranges;

			clocks = <&gcc GCC_CFG_NOC_USB3_SEC_AXI_CLK>,
				 <&gcc GCC_USB30_SEC_MASTER_CLK>,
				 <&gcc GCC_AGGRE_USB3_SEC_AXI_CLK>,
				 <&gcc GCC_USB30_SEC_MOCK_UTMI_CLK>,
				 <&gcc GCC_USB30_SEC_SLEEP_CLK>;
			clock-names = "cfg_noc", "core", "iface", "mock_utmi",
				      "sleep";

			assigned-clocks = <&gcc GCC_USB30_SEC_MOCK_UTMI_CLK>,
					  <&gcc GCC_USB30_SEC_MASTER_CLK>;
			assigned-clock-rates = <19200000>, <150000000>;

			interrupts = <GIC_SPI 136 IRQ_TYPE_LEVEL_HIGH>,
				     <GIC_SPI 487 IRQ_TYPE_LEVEL_HIGH>,
				     <GIC_SPI 490 IRQ_TYPE_LEVEL_HIGH>,
				     <GIC_SPI 491 IRQ_TYPE_LEVEL_HIGH>;
			interrupt-names = "hs_phy_irq", "ss_phy_irq",
					  "dm_hs_phy_irq", "dp_hs_phy_irq";

			power-domains = <&gcc USB30_SEC_GDSC>;

			resets = <&gcc GCC_USB30_SEC_BCR>;

			usb_2_dwc3: dwc3@a800000 {
				compatible = "snps,dwc3";
				reg = <0xa800000 0xcd00>;
				interrupts = <GIC_SPI 138 IRQ_TYPE_LEVEL_HIGH>;
				snps,dis_u2_susphy_quirk;
				snps,dis_enblslpm_quirk;
				phys = <&usb_2_hsphy>, <&usb_2_ssphy>;
				phy-names = "usb2-phy", "usb3-phy";
			};
		};

		video-codec@aa00000 {
			compatible = "qcom,sdm845-venus";
			reg = <0x0aa00000 0xff000>;
			interrupts = <GIC_SPI 174 IRQ_TYPE_LEVEL_HIGH>;
			power-domains = <&videocc VENUS_GDSC>;
			clocks = <&videocc VIDEO_CC_VENUS_CTL_CORE_CLK>,
				<&videocc VIDEO_CC_VENUS_AHB_CLK>,
				<&videocc VIDEO_CC_VENUS_CTL_AXI_CLK>;
			clock-names = "core", "iface", "bus";
			iommus = <&apps_smmu 0x10a0 0x8>,
				<&apps_smmu 0x10b0 0x0>;
			memory-region = <&venus_region>;
			interconnects = <&qnoc 42 &qnoc 512>;
			interconnect-names = "video";

			video-core0 {
				compatible = "venus-decoder";
				clocks = <&videocc VIDEO_CC_VCODEC0_CORE_CLK>,
					<&videocc VIDEO_CC_VCODEC0_AXI_CLK>;
				clock-names = "core", "bus";
				power-domains = <&videocc VCODEC0_GDSC>;
			};

			video-core1 {
				compatible = "venus-encoder";
				clocks = <&videocc VIDEO_CC_VCODEC1_CORE_CLK>,
					<&videocc VIDEO_CC_VCODEC1_AXI_CLK>;
				clock-names = "core", "bus";
				power-domains = <&videocc VCODEC1_GDSC>;
			};

			firmware {
				compatible = "qcom,venus-firmware";
				iommus = <&apps_smmu 0x10b2 0x0>;
			};
		};

		videocc: clock-controller@ab00000 {
			compatible = "qcom,sdm845-videocc";
			reg = <0xab00000 0x10000>;
			#clock-cells = <1>;
			#reset-cells = <1>;
			#power-domain-cells = <1>;
		};

		mdss: mdss@ae00000 {
			compatible = "qcom,sdm845-mdss";
			reg = <0xae00000 0x1000>;
			reg-names = "mdss";

			power-domains = <&dispcc 0>;

			clocks = <&gcc GCC_DISP_AHB_CLK>,
				 <&gcc GCC_DISP_AXI_CLK>,
				 <&dispcc DISP_CC_MDSS_MDP_CLK>;
			clock-names = "gcc_iface", "gcc_bus", "core";

			assigned-clocks = <&dispcc DISP_CC_MDSS_MDP_CLK>;
			assigned-clock-rates = <300000000>;

			interrupts = <GIC_SPI 83 IRQ_TYPE_LEVEL_HIGH>;
			interrupt-controller;
			#interrupt-cells = <1>;

			interconnects = <&qnoc 38 &qnoc 512>,
					<&qnoc 39 &qnoc 512>;
			interconnect-names = "port0", "port1";

			iommus = <&apps_smmu 0x880 0x8>,
				 <&apps_smmu 0xc80 0x8>;

			#address-cells = <2>;
			#size-cells = <1>;
			ranges = <0 0 0xae00000 0xb2008>;

			mdss_mdp: mdp@ae01000 {
				compatible = "qcom,sdm845-dpu";
				reg = <0 0x1000 0x8f000>, <0 0xb0000 0x2008>;
				reg-names = "mdp", "vbif";

				clocks = <&dispcc DISP_CC_MDSS_AHB_CLK>,
					 <&dispcc DISP_CC_MDSS_AXI_CLK>,
					 <&dispcc DISP_CC_MDSS_MDP_CLK>,
					 <&dispcc DISP_CC_MDSS_VSYNC_CLK>;
				clock-names = "iface", "bus", "core", "vsync";

				assigned-clocks =
					<&dispcc DISP_CC_MDSS_MDP_CLK>,
					<&dispcc DISP_CC_MDSS_VSYNC_CLK>;
				assigned-clock-rates = <300000000 19200000>;

				interrupts = <0 IRQ_TYPE_LEVEL_HIGH>;

				ports {
					#address-cells = <1>;
					#size-cells = <0>;

					port@0 {
						reg = <0>;
						dpu_intf1_out: endpoint {
							remote-endpoint = <&dsi0_in>;
						};
					};

					port@1 {
						reg = <1>;
						dpu_intf2_out: endpoint {
							remote-endpoint = <&dsi1_in>;
						};
					};
				};

			};

			dsi0: dsi@ae94000 {
				compatible = "qcom,mdss-dsi-ctrl";
				reg = <0 0x94000 0x400>;
				reg-names = "dsi_ctrl";

				interrupt-parent = <&mdss>;
				interrupts = <4 IRQ_TYPE_LEVEL_HIGH>;

				clocks = <&dispcc DISP_CC_MDSS_BYTE0_CLK>,
					 <&dispcc DISP_CC_MDSS_BYTE0_INTF_CLK>,
					 <&dispcc DISP_CC_MDSS_PCLK0_CLK>,
					 <&dispcc DISP_CC_MDSS_ESC0_CLK>,
					 <&dispcc DISP_CC_MDSS_AHB_CLK>,
					 <&dispcc DISP_CC_MDSS_AXI_CLK>;
				clock-names = "byte",
					      "byte_intf",
					      "pixel",
					      "core",
					      "iface",
					      "bus";

				phys = <&dsi0_phy>;
				phy-names = "dsi-phy";

				#address-cells = <1>;
				#size-cells = <0>;

				ports {
					#address-cells = <1>;
					#size-cells = <0>;

					port@0 {
						reg = <0>;
						dsi0_in: endpoint {
							remote-endpoint = <&dpu_intf1_out>;
						};
					};

					port@1 {
						reg = <1>;
						dsi0_out: endpoint {
						};
					};
				};
			};

			dsi0_phy: dsi-phy@ae94400 {
				compatible = "qcom,dsi-phy-10nm";
				reg = <0 0x94400 0x200>,
				      <0 0x94a00 0x1e0>,
				      <0 0x94600 0x280>;
				reg-names = "dsi_phy",
					    "dsi_pll",
						"dsi_phy_lane";

				#clock-cells = <1>;
				#phy-cells =<0>;

				clocks = <&dispcc DISP_CC_MDSS_AHB_CLK>;
				clock-names = "iface";
			};

			dsi1: dsi@ae96000 {
				compatible = "qcom,mdss-dsi-ctrl";
				reg = <0 0x96000 0x400>;
				reg-names = "dsi_ctrl";

				interrupt-parent = <&mdss>;
				interrupts = <5 IRQ_TYPE_LEVEL_HIGH>;

				clocks = <&dispcc DISP_CC_MDSS_BYTE1_CLK>,
					 <&dispcc DISP_CC_MDSS_BYTE1_INTF_CLK>,
					 <&dispcc DISP_CC_MDSS_PCLK1_CLK>,
					 <&dispcc DISP_CC_MDSS_ESC1_CLK>,
					 <&dispcc DISP_CC_MDSS_AHB_CLK>,
					 <&dispcc DISP_CC_MDSS_AXI_CLK>;
				clock-names = "byte",
					      "byte_intf",
					      "pixel",
					      "core",
					      "iface",
					      "bus";

				phys = <&dsi1_phy>;
				phy-names = "dsi-phy";

				#address-cells = <1>;
				#size-cells = <0>;

				ports {
					#address-cells = <1>;
					#size-cells = <0>;

					port@0 {
						reg = <0>;
						dsi1_in: endpoint {
							remote-endpoint = <&dpu_intf2_out>;
						};
					};

					port@1 {
						reg = <1>;
						dsi1_out: endpoint {
						};
					};
				};
			};

			dsi1_phy: dsi-phy@ae96400 {
				compatible = "qcom,dsi-phy-10nm";
				reg = <0 0x96400 0x200>,
				      <0 0x96a00 0x10e>,
					<0 0x96600 0x280>;
				reg-names = "dsi_phy",
					    "dsi_pll",
						"dsi_phy_lane";

				#clock-cells = <1>;
				#phy-cells =<0>;

				clocks = <&dispcc DISP_CC_MDSS_AHB_CLK>;
				clock-names = "iface";
			};
		};

		dispcc: clock-controller@af00000 {
			compatible = "qcom,sdm845-dispcc";
			reg = <0xaf00000 0x10000>;
			#clock-cells = <1>;
			#reset-cells = <1>;
			#power-domain-cells = <1>;
		};

		pdc_reset: reset-controller@b2e0000 {
			compatible = "qcom,sdm845-pdc-global";
			reg = <0xb2e0000 0x20000>;
			#reset-cells = <1>;
		};

		tsens0: thermal-sensor@c263000 {
			compatible = "qcom,sdm845-tsens", "qcom,tsens-v2";
			reg = <0xc263000 0x1ff>, /* TM */
			      <0xc222000 0x1ff>; /* SROT */
			#qcom,sensors = <13>;
			#thermal-sensor-cells = <1>;
		};

		restart@c264000 {
			compatible = "qcom,pshold";
			reg = <0xc264000 0x4>;
			qcom,dload-mode = <&tcsr 0x13000>;
		};

		tsens1: thermal-sensor@c265000 {
			compatible = "qcom,sdm845-tsens", "qcom,tsens-v2";
			reg = <0xc265000 0x1ff>, /* TM */
			      <0xc223000 0x1ff>; /* SROT */
			#qcom,sensors = <8>;
			#thermal-sensor-cells = <1>;
		};

		aoss_reset: reset-controller@c2a0000 {
			compatible = "qcom,sdm845-aoss-cc";
			reg = <0xc2a0000 0x31000>;
			#reset-cells = <1>;
		};

		spmi_bus: spmi@c440000 {
			compatible = "qcom,spmi-pmic-arb";
			reg = <0xc440000 0x1100>,
			      <0xc600000 0x2000000>,
			      <0xe600000 0x100000>,
			      <0xe700000 0xa0000>,
			      <0xc40a000 0x26000>;
			reg-names = "core", "chnls", "obsrvr", "intr", "cnfg";
			interrupt-names = "periph_irq";
			interrupts = <GIC_SPI 481 IRQ_TYPE_LEVEL_HIGH>;
			qcom,ee = <0>;
			qcom,channel = <0>;
			#address-cells = <2>;
			#size-cells = <0>;
			interrupt-controller;
			#interrupt-cells = <4>;
			cell-index = <0>;
		};

		apps_smmu: iommu@15000000 {
			compatible = "qcom,sdm845-smmu-500", "arm,mmu-500";
			reg = <0x15000000 0x80000>;
			#iommu-cells = <2>;
			#global-interrupts = <1>;
			interrupts = <GIC_SPI 65 IRQ_TYPE_LEVEL_HIGH>,
				     <GIC_SPI 96 IRQ_TYPE_LEVEL_HIGH>,
				     <GIC_SPI 97 IRQ_TYPE_LEVEL_HIGH>,
				     <GIC_SPI 98 IRQ_TYPE_LEVEL_HIGH>,
				     <GIC_SPI 99 IRQ_TYPE_LEVEL_HIGH>,
				     <GIC_SPI 100 IRQ_TYPE_LEVEL_HIGH>,
				     <GIC_SPI 101 IRQ_TYPE_LEVEL_HIGH>,
				     <GIC_SPI 102 IRQ_TYPE_LEVEL_HIGH>,
				     <GIC_SPI 103 IRQ_TYPE_LEVEL_HIGH>,
				     <GIC_SPI 104 IRQ_TYPE_LEVEL_HIGH>,
				     <GIC_SPI 105 IRQ_TYPE_LEVEL_HIGH>,
				     <GIC_SPI 106 IRQ_TYPE_LEVEL_HIGH>,
				     <GIC_SPI 107 IRQ_TYPE_LEVEL_HIGH>,
				     <GIC_SPI 108 IRQ_TYPE_LEVEL_HIGH>,
				     <GIC_SPI 109 IRQ_TYPE_LEVEL_HIGH>,
				     <GIC_SPI 110 IRQ_TYPE_LEVEL_HIGH>,
				     <GIC_SPI 111 IRQ_TYPE_LEVEL_HIGH>,
				     <GIC_SPI 112 IRQ_TYPE_LEVEL_HIGH>,
				     <GIC_SPI 113 IRQ_TYPE_LEVEL_HIGH>,
				     <GIC_SPI 114 IRQ_TYPE_LEVEL_HIGH>,
				     <GIC_SPI 115 IRQ_TYPE_LEVEL_HIGH>,
				     <GIC_SPI 116 IRQ_TYPE_LEVEL_HIGH>,
				     <GIC_SPI 117 IRQ_TYPE_LEVEL_HIGH>,
				     <GIC_SPI 118 IRQ_TYPE_LEVEL_HIGH>,
				     <GIC_SPI 181 IRQ_TYPE_LEVEL_HIGH>,
				     <GIC_SPI 182 IRQ_TYPE_LEVEL_HIGH>,
				     <GIC_SPI 183 IRQ_TYPE_LEVEL_HIGH>,
				     <GIC_SPI 184 IRQ_TYPE_LEVEL_HIGH>,
				     <GIC_SPI 185 IRQ_TYPE_LEVEL_HIGH>,
				     <GIC_SPI 186 IRQ_TYPE_LEVEL_HIGH>,
				     <GIC_SPI 187 IRQ_TYPE_LEVEL_HIGH>,
				     <GIC_SPI 188 IRQ_TYPE_LEVEL_HIGH>,
				     <GIC_SPI 189 IRQ_TYPE_LEVEL_HIGH>,
				     <GIC_SPI 190 IRQ_TYPE_LEVEL_HIGH>,
				     <GIC_SPI 191 IRQ_TYPE_LEVEL_HIGH>,
				     <GIC_SPI 192 IRQ_TYPE_LEVEL_HIGH>,
				     <GIC_SPI 315 IRQ_TYPE_LEVEL_HIGH>,
				     <GIC_SPI 316 IRQ_TYPE_LEVEL_HIGH>,
				     <GIC_SPI 317 IRQ_TYPE_LEVEL_HIGH>,
				     <GIC_SPI 318 IRQ_TYPE_LEVEL_HIGH>,
				     <GIC_SPI 319 IRQ_TYPE_LEVEL_HIGH>,
				     <GIC_SPI 320 IRQ_TYPE_LEVEL_HIGH>,
				     <GIC_SPI 321 IRQ_TYPE_LEVEL_HIGH>,
				     <GIC_SPI 322 IRQ_TYPE_LEVEL_HIGH>,
				     <GIC_SPI 323 IRQ_TYPE_LEVEL_HIGH>,
				     <GIC_SPI 324 IRQ_TYPE_LEVEL_HIGH>,
				     <GIC_SPI 325 IRQ_TYPE_LEVEL_HIGH>,
				     <GIC_SPI 326 IRQ_TYPE_LEVEL_HIGH>,
				     <GIC_SPI 327 IRQ_TYPE_LEVEL_HIGH>,
				     <GIC_SPI 328 IRQ_TYPE_LEVEL_HIGH>,
				     <GIC_SPI 329 IRQ_TYPE_LEVEL_HIGH>,
				     <GIC_SPI 330 IRQ_TYPE_LEVEL_HIGH>,
				     <GIC_SPI 331 IRQ_TYPE_LEVEL_HIGH>,
				     <GIC_SPI 332 IRQ_TYPE_LEVEL_HIGH>,
				     <GIC_SPI 333 IRQ_TYPE_LEVEL_HIGH>,
				     <GIC_SPI 334 IRQ_TYPE_LEVEL_HIGH>,
				     <GIC_SPI 335 IRQ_TYPE_LEVEL_HIGH>,
				     <GIC_SPI 336 IRQ_TYPE_LEVEL_HIGH>,
				     <GIC_SPI 337 IRQ_TYPE_LEVEL_HIGH>,
				     <GIC_SPI 338 IRQ_TYPE_LEVEL_HIGH>,
				     <GIC_SPI 339 IRQ_TYPE_LEVEL_HIGH>,
				     <GIC_SPI 340 IRQ_TYPE_LEVEL_HIGH>,
				     <GIC_SPI 341 IRQ_TYPE_LEVEL_HIGH>,
				     <GIC_SPI 342 IRQ_TYPE_LEVEL_HIGH>,
				     <GIC_SPI 343 IRQ_TYPE_LEVEL_HIGH>;
		};

		watchdog@17980000{
			compatible = "qcom,kpss-wdt";
			reg = <0x17980000 0x1000>;
			clocks = <&sleep_clk>;
		};

		apss_shared: mailbox@17990000 {
			compatible = "qcom,sdm845-apss-shared";
			reg = <0x17990000 0x1000>;
			#mbox-cells = <1>;
		};

		apps_rsc: rsc@179c0000 {
			label = "apps_rsc";
			compatible = "qcom,rpmh-rsc";
			reg = <0x179c0000 0x10000>,
			      <0x179d0000 0x10000>,
			      <0x179e0000 0x10000>;
			reg-names = "drv-0", "drv-1", "drv-2";
			interrupts = <GIC_SPI 3 IRQ_TYPE_LEVEL_HIGH>,
				     <GIC_SPI 4 IRQ_TYPE_LEVEL_HIGH>,
				     <GIC_SPI 5 IRQ_TYPE_LEVEL_HIGH>;
			qcom,tcs-offset = <0xd00>;
			qcom,drv-id = <2>;
			qcom,tcs-config = <ACTIVE_TCS  2>,
					  <SLEEP_TCS   3>,
					  <WAKE_TCS    3>,
					  <CONTROL_TCS 1>;

			cpu_pd: power-domain-controller {
				compatible = "qcom,cpu-pm-domain";
				#power-domain-cells = <0>;
			};

			rpmhcc: clock-controller {
				compatible = "qcom,sdm845-rpmh-clk";
				#clock-cells = <1>;
			};

			rpmhpd_opp_table: opp-table {
				compatible = "operating-points-v2-qcom-level";

				rpmhpd_opp_ret: opp1 {
					qcom,level = <RPMH_REGULATOR_LEVEL_RETENTION>;
				};

				rpmhpd_opp_min_svs: opp2 {
					qcom,level = <RPMH_REGULATOR_LEVEL_MIN_SVS>;
				};

				rpmhpd_opp_low_svs: opp3 {
					qcom,level = <RPMH_REGULATOR_LEVEL_LOW_SVS>;
				};

				rpmhpd_opp_svs: opp4 {
					qcom,level = <RPMH_REGULATOR_LEVEL_SVS>;
				};

				rpmhpd_opp_svs_l1: opp5 {
					qcom,level = <RPMH_REGULATOR_LEVEL_SVS_L1>;
				};

				rpmhpd_opp_nom: opp6 {
					qcom,level = <RPMH_REGULATOR_LEVEL_NOM>;
				};

				rpmhpd_opp_nom_l1: opp7 {
					qcom,level = <RPMH_REGULATOR_LEVEL_NOM_L1>;
				};

				rpmhpd_opp_nom_l2: opp8 {
					qcom,level = <RPMH_REGULATOR_LEVEL_NOM_L2>;
				};

				rpmhpd_opp_turbo: opp9 {
					qcom,level = <RPMH_REGULATOR_LEVEL_TURBO>;
				};

				rpmhpd_opp_turbo_l1: opp10 {
					qcom,level = <RPMH_REGULATOR_LEVEL_TURBO_L1>;
				};
			};

			rpmhpd: power-controller {
				compatible = "qcom,sdm845-rpmhpd";
				#power-domain-cells = <1>;
				operating-points-v2 = <&rpmhpd_opp_table>;
			};

			qnoc: qnoc{
				compatible = "qcom,sdm845-rsc-hlos";
				#interconnect-cells = <1>;
			};
		};

		intc: interrupt-controller@17a00000 {
			compatible = "arm,gic-v3";
			#address-cells = <1>;
			#size-cells = <1>;
			ranges;
			#interrupt-cells = <3>;
			interrupt-controller;
			reg = <0x17a00000 0x10000>,     /* GICD */
			      <0x17a60000 0x100000>;    /* GICR * 8 */
			interrupts = <GIC_PPI 9 IRQ_TYPE_LEVEL_HIGH>;

			gic-its@17a40000 {
				compatible = "arm,gic-v3-its";
				msi-controller;
				#msi-cells = <1>;
				reg = <0x17a40000 0x20000>;
				status = "disabled";
			};
		};

		pdc: interrupt-controller@b220000 {
			compatible = "qcom,sdm845-pdc";
			reg = <0xb220000 0x30000>;
			qcom,pdc-ranges = <0 480 94>, <94 609 15>, <115 630 7>;
			#interrupt-cells = <2>;
			interrupt-parent = <&intc>;
			interrupt-controller;
		};

		timer@17c90000 {
			#address-cells = <1>;
			#size-cells = <1>;
			ranges;
			compatible = "arm,armv7-timer-mem";
			reg = <0x17c90000 0x1000>;

			frame@17ca0000 {
				frame-number = <0>;
				interrupts = <GIC_SPI 7 IRQ_TYPE_LEVEL_HIGH>,
					     <GIC_SPI 6 IRQ_TYPE_LEVEL_HIGH>;
				reg = <0x17ca0000 0x1000>,
				      <0x17cb0000 0x1000>;
			};

			frame@17cc0000 {
				frame-number = <1>;
				interrupts = <GIC_SPI 8 IRQ_TYPE_LEVEL_HIGH>;
				reg = <0x17cc0000 0x1000>;
				status = "disabled";
			};

			frame@17cd0000 {
				frame-number = <2>;
				interrupts = <GIC_SPI 9 IRQ_TYPE_LEVEL_HIGH>;
				reg = <0x17cd0000 0x1000>;
				status = "disabled";
			};

			frame@17ce0000 {
				frame-number = <3>;
				interrupts = <GIC_SPI 10 IRQ_TYPE_LEVEL_HIGH>;
				reg = <0x17ce0000 0x1000>;
				status = "disabled";
			};

			frame@17cf0000 {
				frame-number = <4>;
				interrupts = <GIC_SPI 11 IRQ_TYPE_LEVEL_HIGH>;
				reg = <0x17cf0000 0x1000>;
				status = "disabled";
			};

			frame@17d00000 {
				frame-number = <5>;
				interrupts = <GIC_SPI 12 IRQ_TYPE_LEVEL_HIGH>;
				reg = <0x17d00000 0x1000>;
				status = "disabled";
			};

			frame@17d10000 {
				frame-number = <6>;
				interrupts = <GIC_SPI 13 IRQ_TYPE_LEVEL_HIGH>;
				reg = <0x17d10000 0x1000>;
				status = "disabled";
			};
		};

		cpufreq_hw: cpufreq@17d43000 {
			compatible = "qcom,cpufreq-hw";

			reg = <0x17d43000 0x1400>, <0x17d45800 0x1400>;
			reg-names = "freq-domain0", "freq-domain1";

			clocks = <&rpmhcc RPMH_CXO_CLK>, <&gcc GPLL0>;
			clock-names = "xo", "cpu_clk";

			#freq-domain-cells = <1>;
		};

		qmp_aop: qcom,qmp-aop@c300000 {
			compatible = "qcom,qmp-mbox";
			label = "aop";
			reg = <0xc300000 0x100000>,
				<0x1799000c 0x4>;
			reg-names = "msgram", "irq-reg-base";
			qcom,irq-mask = <0x1>;
			interrupts = <0 389 1>;
			priority = <0>;
			mbox-desc-offset = <0x0>;
			#mbox-cells = <1>;
		};

		adreno_smmu: arm,smmu-adreno@5040000 {
			compatible = "qcom,sdm845-smmu-v2", "qcom,smmu-v2";
			reg = <0x5040000 0x10000>;
			#iommu-cells = <1>;
			#global-interrupts = <2>;
			interrupts = <GIC_SPI 229 IRQ_TYPE_LEVEL_HIGH>,
			     <GIC_SPI 231 IRQ_TYPE_LEVEL_HIGH>,
			     <GIC_SPI 364 IRQ_TYPE_EDGE_RISING>,
			     <GIC_SPI 365 IRQ_TYPE_EDGE_RISING>,
			     <GIC_SPI 366 IRQ_TYPE_EDGE_RISING>,
			     <GIC_SPI 367 IRQ_TYPE_EDGE_RISING>,
			     <GIC_SPI 368 IRQ_TYPE_EDGE_RISING>,
			     <GIC_SPI 369 IRQ_TYPE_EDGE_RISING>,
			     <GIC_SPI 370 IRQ_TYPE_EDGE_RISING>,
			     <GIC_SPI 371 IRQ_TYPE_EDGE_RISING>;
			clocks = <&gcc GCC_GPU_MEMNOC_GFX_CLK>,
				<&gcc GCC_GPU_CFG_AHB_CLK>;
			clock-names = "bus", "iface";

			power-domains = <&gpucc GPU_CX_GDSC>;
		};

		gpu_opp_table: adreno-opp-table {
			compatible = "operating-points-v2";

			opp-710000000 {
				opp-hz = /bits/ 64 <710000000>;
				qcom,level = <416>;
				opp-interconnect-bw-port0 = /bits/ 64 <0 7216000000>;
			};

			opp-675000000 {
				opp-hz = /bits/ 64 <675000000>;
				qcom,level = <384>;
				opp-interconnect-bw-port0 = /bits/ 64 <0 7216000000>;
			};

			opp-596000000 {
				opp-hz = /bits/ 64 <596000000>;
				qcom,level = <320>;
				opp-interconnect-bw-port0 = /bits/ 64 <0 5184000000>;
			};

			opp-520000000 {
				opp-hz = /bits/ 64 <520000000>;
				qcom,level = <256>;
				opp-interconnect-bw-port0 = /bits/ 64 <0 4068000000>;
			};

			opp-414000000 {
				opp-hz = /bits/ 64 <414000000>;
				qcom,level = <192>;
				opp-interconnect-bw-port0 = /bits/ 64 <0 3072000000>;
			};

			opp-342000000 {
				opp-hz = /bits/ 64 <342000000>;
				qcom,level = <128>;
				opp-interconnect-bw-port0 = /bits/ 64 <0 2188000000>;
			};

			opp-257000000 {
				opp-hz = /bits/ 64 <257000000>;
				qcom,level = <64>;
				opp-interconnect-bw-port0 = /bits/ 64 <0 1200000000>;
			};
		};

		gpu@5000000 {
			compatible = "qcom,adreno-630.2", "qcom,adreno";
			#stream-id-cells = <16>;

			reg = <0x5000000 0x40000>;
			reg-names = "kgsl_3d0_reg_memory";

			/*
			 * Look ma, no clocks! The GPU clocks and power are
			 * controlled entirely by the GMU
			 */

			interrupts = <0 300 0>;
			interrupt-names = "kgsl_3d0_irq";

			iommus = <&adreno_smmu 0>;

			operating-points-v2 = <&gpu_opp_table>;

			interconnects = <&qnoc 36 &qnoc 512>;
			interconnect-names = "port0";

			qcom,gmu = <&gmu>;
		};

		gmu_opp_table: adreno-gmu-opp-table {
			compatible = "operating-points-v2";

			opp-400000000 {
				opp-hz = /bits/ 64 <400000000>;
				qcom,level = <128>;
			};

			opp-200000000 {
				opp-hz = /bits/ 64 <200000000>;
				qcom,level = <48>;
			};
		};

		gmu: gmu@506a000 {
			compatible="qcom,adreno-gmu";

			reg = <0x506a000 0x30000>,
				<0xb280000 0x10000>,
				<0xb480000 0x10000>;
			reg-names = "gmu", "gmu_pdc", "gmu_pdc_seq";

			interrupts = <GIC_SPI 304 IRQ_TYPE_LEVEL_HIGH>,
			     <GIC_SPI 305 IRQ_TYPE_LEVEL_HIGH>;
			interrupt-names = "hfi", "gmu";

			clocks = <&gpucc GPU_CC_CX_GMU_CLK>,
				<&gpucc GPU_CC_CXO_CLK>,
				<&gcc GCC_DDRSS_GPU_AXI_CLK>,
				<&gcc GCC_GPU_MEMNOC_GFX_CLK>;
			clock-names = "gmu", "cxo", "axi", "memnoc";

			power-domains = <&gpucc GPU_CX_GDSC>;
			iommus = <&adreno_smmu 5>;

			operating-points-v2 = <&gmu_opp_table>;
		};

		wifi: wifi {
			compatible = "qcom,wcn3990-wifi";
			reg = <0x18800000 0x800000>;
			reg-names = "membase";
			status = "disabled";
			memory-region = <&wlan_msa_mem>;
			iommus = <&apps_smmu 0x0040 0x1>;
			interrupts =
				<0 413 0 /* CE0 */ >,
				<0 414 0 /* CE1 */ >,
				<0 415 0 /* CE2 */ >,
				<0 416 0 /* CE3 */ >,
				<0 417 0 /* CE4 */ >,
				<0 418 0 /* CE5 */ >,
				<0 420 0 /* CE6 */ >,
				<0 421 0 /* CE7 */ >,
				<0 422 0 /* CE8 */ >,
				<0 423 0 /* CE9 */ >,
				<0 424 0 /* CE10 */ >,
				<0 425 0 /* CE11 */ >;
		};
	};

	thermal-zones {
		cpu0-thermal {
			polling-delay-passive = <250>;
			polling-delay = <1000>;

			thermal-sensors = <&tsens0 1>;

			trips {
				cpu_alert0: trip0 {
					temperature = <75000>;
					hysteresis = <2000>;
					type = "passive";
				};

				cpu_crit0: trip1 {
					temperature = <110000>;
					hysteresis = <1000>;
					type = "critical";
				};
			};

			cooling-maps {
				map0 {
					trip = <&cpu_alert0>;
					cooling-device =
						<&CPU0 THERMAL_NO_LIMIT THERMAL_NO_LIMIT>;
				};
			};
		};

		cpu1-thermal {
			polling-delay-passive = <250>;
			polling-delay = <1000>;

			thermal-sensors = <&tsens0 2>;

			trips {
				cpu_alert1: trip0 {
					temperature = <75000>;
					hysteresis = <2000>;
					type = "passive";
				};

				cpu_crit1: trip1 {
					temperature = <110000>;
					hysteresis = <1000>;
					type = "critical";
				};
			};

			cooling-maps {
				map0 {
					trip = <&cpu_alert1>;
					cooling-device =
						<&CPU0 THERMAL_NO_LIMIT THERMAL_NO_LIMIT>;
				};
			};
		};

		cpu2-thermal {
			polling-delay-passive = <250>;
			polling-delay = <1000>;

			thermal-sensors = <&tsens0 3>;

			trips {
				cpu_alert2: trip0 {
					temperature = <75000>;
					hysteresis = <2000>;
					type = "passive";
				};

				cpu_crit2: trip1 {
					temperature = <110000>;
					hysteresis = <1000>;
					type = "critical";
				};
			};

			cooling-maps {
				map0 {
					trip = <&cpu_alert2>;
					cooling-device =
						<&CPU0 THERMAL_NO_LIMIT THERMAL_NO_LIMIT>;
				};
			};
		};

		cpu3-thermal {
			polling-delay-passive = <250>;
			polling-delay = <1000>;

			thermal-sensors = <&tsens0 4>;

			trips {
				cpu_alert3: trip0 {
					temperature = <75000>;
					hysteresis = <2000>;
					type = "passive";
				};

				cpu_crit3: trip1 {
					temperature = <110000>;
					hysteresis = <1000>;
					type = "critical";
				};
			};

			cooling-maps {
				map0 {
					trip = <&cpu_alert3>;
					cooling-device =
						<&CPU0 THERMAL_NO_LIMIT THERMAL_NO_LIMIT>;
				};
			};
		};

		cpu4-thermal {
			polling-delay-passive = <250>;
			polling-delay = <1000>;

			thermal-sensors = <&tsens0 7>;

			trips {
				cpu_alert4: trip0 {
					temperature = <75000>;
					hysteresis = <2000>;
					type = "passive";
				};

				cpu_crit4: trip1 {
					temperature = <110000>;
					hysteresis = <1000>;
					type = "critical";
				};
			};

			cooling-maps {
				map0 {
					trip = <&cpu_alert4>;
					cooling-device =
						<&CPU4 THERMAL_NO_LIMIT THERMAL_NO_LIMIT>;
				};
			};
		};

		cpu5-thermal {
			polling-delay-passive = <250>;
			polling-delay = <1000>;

			thermal-sensors = <&tsens0 8>;

			trips {
				cpu_alert5: trip0 {
					temperature = <75000>;
					hysteresis = <2000>;
					type = "passive";
				};

				cpu_crit5: trip1 {
					temperature = <110000>;
					hysteresis = <1000>;
					type = "critical";
				};
			};

			cooling-maps {
				map0 {
					trip = <&cpu_alert5>;
					cooling-device =
						<&CPU4 THERMAL_NO_LIMIT THERMAL_NO_LIMIT>;
				};
			};
		};

		cpu6-thermal {
			polling-delay-passive = <250>;
			polling-delay = <1000>;

			thermal-sensors = <&tsens0 9>;

			trips {
				cpu_alert6: trip0 {
					temperature = <75000>;
					hysteresis = <2000>;
					type = "passive";
				};

				cpu_crit6: trip1 {
					temperature = <110000>;
					hysteresis = <1000>;
					type = "critical";
				};
			};

			cooling-maps {
				map0 {
					trip = <&cpu_alert6>;
					cooling-device =
						<&CPU4 THERMAL_NO_LIMIT THERMAL_NO_LIMIT>;
				};
			};
		};

		cpu7-thermal {
			polling-delay-passive = <250>;
			polling-delay = <1000>;

			thermal-sensors = <&tsens0 10>;

			trips {
				cpu_alert7: trip0 {
					temperature = <75000>;
					hysteresis = <2000>;
					type = "passive";
				};

				cpu_crit7: trip1 {
					temperature = <110000>;
					hysteresis = <1000>;
					type = "critical";
				};
			};

			cooling-maps {
				map0 {
					trip = <&cpu_alert7>;
					cooling-device =
						<&CPU4 THERMAL_NO_LIMIT THERMAL_NO_LIMIT>;
				};
			};
		};
	};
};

#include "pm8998.dtsi"
/*
 * TODO: the below isn't the right way to do this; this is all just hacks
 * until we have patches to do this right.
 */
